// Description: LIN Description file created using Vector's DaVinci Network Designer

// Created: 16 Dec 2021 13:01:28

// Author: A048997

// Version: 0.0

// COM_MATRIX_T2_1.24.X1

LIN_description_file;
LIN_protocol_version = "2.1";
LIN_language_version = "2.1";
LIN_speed = 19.2 kbps;

Nodes {
  Master: CCM, 5 ms, 0.5 ms ;
  Slaves: HVACActuator_1, HVACActuator_2, HVACActuator_3, HVACActuator_4, HVACActuator_5 ;
}

Signals {
  HVACAct1Cmd_ConfigDir: 2, 1, CCM, HVACActuator_1 ;
  HVACAct1Cmd_ConfigEmRun: 2, 1, CCM, HVACActuator_1 ;
  HVACAct1Cmd_ConfigEmRunDir: 2, 0, CCM, HVACActuator_1 ;
  HVACAct1Cmd_ConfigMode: 2, 1, CCM, HVACActuator_1 ;
  HVACAct1Cmd_CtrlClearFlags: 4, 0, CCM, HVACActuator_1 ;
  HVACAct1Cmd_CtrlLoadData: 2, 0, CCM, HVACActuator_1 ;
  HVACAct1Cmd_CtrlStallEn: 2, 1, CCM, HVACActuator_1 ;
  HVACAct1Cmd_FPOS: 16, 65535, CCM, HVACActuator_1 ;
  HVACAct1Cmd_InitPOS: 16, 65535, CCM, HVACActuator_1 ;
  HVACAct1Cmd_NAD: 8, 255, CCM, HVACActuator_1 ;
  HVACAct1Cmd_ParamCoils: 2, 0, CCM, HVACActuator_1 ;
  HVACAct1Cmd_ParamFreq: 4, 1, CCM, HVACActuator_1 ;
  HVACAct1Cmd_ParamPosMode: 2, 2, CCM, HVACActuator_1 ;
  HVACAct2Cmd_ConfigDir: 2, 1, CCM, HVACActuator_2 ;
  HVACAct2Cmd_ConfigEmRun: 2, 1, CCM, HVACActuator_2 ;
  HVACAct2Cmd_ConfigEmRunDir: 2, 0, CCM, HVACActuator_2 ;
  HVACAct2Cmd_ConfigMode: 2, 1, CCM, HVACActuator_2 ;
  HVACAct2Cmd_CtrlClearFlags: 4, 0, CCM, HVACActuator_2 ;
  HVACAct2Cmd_CtrlLoadData: 2, 0, CCM, HVACActuator_2 ;
  HVACAct2Cmd_CtrlStallEn: 2, 1, CCM, HVACActuator_2 ;
  HVACAct2Cmd_FPOS: 16, 65535, CCM, HVACActuator_2 ;
  HVACAct2Cmd_InitPOS: 16, 65535, CCM, HVACActuator_2 ;
  HVACAct2Cmd_NAD: 8, 255, CCM, HVACActuator_2 ;
  HVACAct2Cmd_ParamCoils: 2, 0, CCM, HVACActuator_2 ;
  HVACAct2Cmd_ParamFreq: 4, 1, CCM, HVACActuator_2 ;
  HVACAct2Cmd_ParamPosMode: 2, 2, CCM, HVACActuator_2 ;
  HVACAct3Cmd_ConfigDir: 2, 1, CCM, HVACActuator_3 ;
  HVACAct3Cmd_ConfigEmRun: 2, 1, CCM, HVACActuator_3 ;
  HVACAct3Cmd_ConfigEmRunDir: 2, 0, CCM, HVACActuator_3 ;
  HVACAct3Cmd_ConfigMode: 2, 1, CCM, HVACActuator_3 ;
  HVACAct3Cmd_CtrlClearFlags: 4, 0, CCM, HVACActuator_3 ;
  HVACAct3Cmd_CtrlLoadData: 2, 0, CCM, HVACActuator_3 ;
  HVACAct3Cmd_CtrlStallEn: 2, 1, CCM, HVACActuator_3 ;
  HVACAct3Cmd_FPOS: 16, 65535, CCM, HVACActuator_3 ;
  HVACAct3Cmd_InitPOS: 16, 65535, CCM, HVACActuator_3 ;
  HVACAct3Cmd_NAD: 8, 255, CCM, HVACActuator_3 ;
  HVACAct3Cmd_ParamCoils: 2, 0, CCM, HVACActuator_3 ;
  HVACAct3Cmd_ParamFreq: 4, 1, CCM, HVACActuator_3 ;
  HVACAct3Cmd_ParamPosMode: 2, 2, CCM, HVACActuator_3 ;
  HVACAct4Cmd_ConfigDir: 2, 1, CCM, HVACActuator_4 ;
  HVACAct4Cmd_ConfigEmRun: 2, 1, CCM, HVACActuator_4 ;
  HVACAct4Cmd_ConfigEmRunDir: 2, 0, CCM, HVACActuator_4 ;
  HVACAct4Cmd_ConfigMode: 2, 1, CCM, HVACActuator_4 ;
  HVACAct4Cmd_CtrlClearFlags: 4, 0, CCM, HVACActuator_4 ;
  HVACAct4Cmd_CtrlLoadData: 2, 0, CCM, HVACActuator_4 ;
  HVACAct4Cmd_CtrlStallEn: 2, 1, CCM, HVACActuator_4 ;
  HVACAct4Cmd_FPOS: 16, 65535, CCM, HVACActuator_4 ;
  HVACAct4Cmd_InitPOS: 16, 65535, CCM, HVACActuator_4 ;
  HVACAct4Cmd_NAD: 8, 255, CCM, HVACActuator_4 ;
  HVACAct4Cmd_ParamCoils: 2, 0, CCM, HVACActuator_4 ;
  HVACAct4Cmd_ParamFreq: 4, 1, CCM, HVACActuator_4 ;
  HVACAct4Cmd_ParamPosMode: 2, 2, CCM, HVACActuator_4 ;
  HVACAct5Cmd_ConfigDir: 2, 1, CCM, HVACActuator_5 ;
  HVACAct5Cmd_ConfigEmRun: 2, 1, CCM, HVACActuator_5 ;
  HVACAct5Cmd_ConfigEmRunDir: 2, 0, CCM, HVACActuator_5 ;
  HVACAct5Cmd_ConfigMode: 2, 1, CCM, HVACActuator_5 ;
  HVACAct5Cmd_CtrlClearFlags: 4, 0, CCM, HVACActuator_5 ;
  HVACAct5Cmd_CtrlLoadData: 2, 0, CCM, HVACActuator_5 ;
  HVACAct5Cmd_CtrlStallEn: 2, 1, CCM, HVACActuator_5 ;
  HVACAct5Cmd_FPOS: 16, 65535, CCM, HVACActuator_5 ;
  HVACAct5Cmd_InitPOS: 16, 65535, CCM, HVACActuator_5 ;
  HVACAct5Cmd_NAD: 8, 255, CCM, HVACActuator_5 ;
  HVACAct5Cmd_ParamCoils: 2, 0, CCM, HVACActuator_5 ;
  HVACAct5Cmd_ParamFreq: 4, 1, CCM, HVACActuator_5 ;
  HVACAct5Cmd_ParamPosMode: 2, 2, CCM, HVACActuator_5 ;
  LIN_HVACAct1Stat_Conf2RunUpDir: 2, 3, HVACActuator_1, CCM ;
  LIN_HVACAct1Stat_Conf2SpecFnc: 2, 3, HVACActuator_1, CCM ;
  LIN_HVACAct1Stat_Conf2TorqueVar: 2, 3, HVACActuator_1, CCM ;
  LIN_HVACAct1Stat_ConfigDir: 2, 1, HVACActuator_1, CCM ;
  LIN_HVACAct1Stat_ConfigEmRun: 2, 0, HVACActuator_1, CCM ;
  LIN_HVACAct1Stat_ConfigEmRunDir: 2, 0, HVACActuator_1, CCM ;
  LIN_HVACAct1Stat_ConfigMode: 2, 1, HVACActuator_1, CCM ;
  LIN_HVACAct1Stat_CurrentPos: 16, 65535, HVACActuator_1, CCM ;
  LIN_HVACAct1Stat_ErrorElectr: 2, 0, HVACActuator_1, CCM ;
  LIN_HVACAct1Stat_ErrorSupply: 2, 0, HVACActuator_1, CCM ;
  LIN_HVACAct1Stat_ErrorTemp: 2, 0, HVACActuator_1, CCM ;
  LIN_HVACAct1Stat_NAD: 8, 255, HVACActuator_1, CCM ;
  LIN_HVACAct1Stat_ParamCoils: 2, 0, HVACActuator_1, CCM ;
  LIN_HVACAct1Stat_ParamFreq: 4, 0, HVACActuator_1, CCM ;
  LIN_HVACAct1Stat_ParamPosMode: 2, 2, HVACActuator_1, CCM ;
  LIN_HVACAct1Stat_ResponseError: 1, 0, HVACActuator_1, CCM ;
  LIN_HVACAct1Stat_StatusEmRun: 2, 0, HVACActuator_1, CCM ;
  LIN_HVACAct1Stat_StatusReset: 2, 0, HVACActuator_1, CCM ;
  LIN_HVACAct1Stat_StatusStall: 2, 0, HVACActuator_1, CCM ;
  LIN_HVACAct1Stat_StatusStallEn: 2, 0, HVACActuator_1, CCM ;
  LIN_HVACAct2Stat_Conf2RunUpDir: 2, 3, HVACActuator_2, CCM ;
  LIN_HVACAct2Stat_Conf2SpecFnc: 2, 3, HVACActuator_2, CCM ;
  LIN_HVACAct2Stat_Conf2TorqueVar: 2, 3, HVACActuator_2, CCM ;
  LIN_HVACAct2Stat_ConfigDir: 2, 1, HVACActuator_2, CCM ;
  LIN_HVACAct2Stat_ConfigEmRun: 2, 0, HVACActuator_2, CCM ;
  LIN_HVACAct2Stat_ConfigEmRunDir: 2, 0, HVACActuator_2, CCM ;
  LIN_HVACAct2Stat_ConfigMode: 2, 1, HVACActuator_2, CCM ;
  LIN_HVACAct2Stat_CurrentPos: 16, 65535, HVACActuator_2, CCM ;
  LIN_HVACAct2Stat_ErrorElectr: 2, 0, HVACActuator_2, CCM ;
  LIN_HVACAct2Stat_ErrorSupply: 2, 0, HVACActuator_2, CCM ;
  LIN_HVACAct2Stat_ErrorTemp: 2, 0, HVACActuator_2, CCM ;
  LIN_HVACAct2Stat_NAD: 8, 255, HVACActuator_2, CCM ;
  LIN_HVACAct2Stat_ParamCoils: 2, 0, HVACActuator_2, CCM ;
  LIN_HVACAct2Stat_ParamFreq: 4, 0, HVACActuator_2, CCM ;
  LIN_HVACAct2Stat_ParamPosMode: 2, 2, HVACActuator_2, CCM ;
  LIN_HVACAct2Stat_ResponseError: 1, 0, HVACActuator_2, CCM ;
  LIN_HVACAct2Stat_StatusEmRun: 2, 0, HVACActuator_2, CCM ;
  LIN_HVACAct2Stat_StatusReset: 2, 0, HVACActuator_2, CCM ;
  LIN_HVACAct2Stat_StatusStall: 2, 0, HVACActuator_2, CCM ;
  LIN_HVACAct2Stat_StatusStallEn: 2, 0, HVACActuator_2, CCM ;
  LIN_HVACAct3Stat_Conf2RunUpDir: 2, 3, HVACActuator_3, CCM ;
  LIN_HVACAct3Stat_Conf2SpecFnc: 2, 3, HVACActuator_3, CCM ;
  LIN_HVACAct3Stat_Conf2TorqueVar: 2, 3, HVACActuator_3, CCM ;
  LIN_HVACAct3Stat_ConfigDir: 2, 1, HVACActuator_3, CCM ;
  LIN_HVACAct3Stat_ConfigEmRun: 2, 0, HVACActuator_3, CCM ;
  LIN_HVACAct3Stat_ConfigEmRunDir: 2, 0, HVACActuator_3, CCM ;
  LIN_HVACAct3Stat_ConfigMode: 2, 1, HVACActuator_3, CCM ;
  LIN_HVACAct3Stat_CurrentPos: 16, 65535, HVACActuator_3, CCM ;
  LIN_HVACAct3Stat_ErrorElectr: 2, 0, HVACActuator_3, CCM ;
  LIN_HVACAct3Stat_ErrorSupply: 2, 0, HVACActuator_3, CCM ;
  LIN_HVACAct3Stat_ErrorTemp: 2, 0, HVACActuator_3, CCM ;
  LIN_HVACAct3Stat_NAD: 8, 255, HVACActuator_3, CCM ;
  LIN_HVACAct3Stat_ParamCoils: 2, 0, HVACActuator_3, CCM ;
  LIN_HVACAct3Stat_ParamFreq: 4, 0, HVACActuator_3, CCM ;
  LIN_HVACAct3Stat_ParamPosMode: 2, 2, HVACActuator_3, CCM ;
  LIN_HVACAct3Stat_ResponseError: 1, 0, HVACActuator_3, CCM ;
  LIN_HVACAct3Stat_StatusEmRun: 2, 0, HVACActuator_3, CCM ;
  LIN_HVACAct3Stat_StatusReset: 2, 0, HVACActuator_3, CCM ;
  LIN_HVACAct3Stat_StatusStall: 2, 0, HVACActuator_3, CCM ;
  LIN_HVACAct3Stat_StatusStallEn: 2, 0, HVACActuator_3, CCM ;
  LIN_HVACAct4Stat_Conf2RunUpDir: 2, 3, HVACActuator_4, CCM ;
  LIN_HVACAct4Stat_Conf2SpecFnc: 2, 3, HVACActuator_4, CCM ;
  LIN_HVACAct4Stat_Conf2TorqueVar: 2, 3, HVACActuator_4, CCM ;
  LIN_HVACAct4Stat_ConfigDir: 2, 1, HVACActuator_4, CCM ;
  LIN_HVACAct4Stat_ConfigEmRun: 2, 0, HVACActuator_4, CCM ;
  LIN_HVACAct4Stat_ConfigEmRunDir: 2, 0, HVACActuator_4, CCM ;
  LIN_HVACAct4Stat_ConfigMode: 2, 1, HVACActuator_4, CCM ;
  LIN_HVACAct4Stat_CurrentPos: 16, 65535, HVACActuator_4, CCM ;
  LIN_HVACAct4Stat_ErrorElectr: 2, 0, HVACActuator_4, CCM ;
  LIN_HVACAct4Stat_ErrorSupply: 2, 0, HVACActuator_4, CCM ;
  LIN_HVACAct4Stat_ErrorTemp: 2, 0, HVACActuator_4, CCM ;
  LIN_HVACAct4Stat_NAD: 8, 255, HVACActuator_4, CCM ;
  LIN_HVACAct4Stat_ParamCoils: 2, 0, HVACActuator_4, CCM ;
  LIN_HVACAct4Stat_ParamFreq: 4, 0, HVACActuator_4, CCM ;
  LIN_HVACAct4Stat_ParamPosMode: 2, 2, HVACActuator_4, CCM ;
  LIN_HVACAct4Stat_ResponseError: 1, 0, HVACActuator_4, CCM ;
  LIN_HVACAct4Stat_StatusEmRun: 2, 0, HVACActuator_4, CCM ;
  LIN_HVACAct4Stat_StatusReset: 2, 0, HVACActuator_4, CCM ;
  LIN_HVACAct4Stat_StatusStall: 2, 0, HVACActuator_4, CCM ;
  LIN_HVACAct4Stat_StatusStallEn: 2, 0, HVACActuator_4, CCM ;
  LIN_HVACAct5Stat_Conf2RunUpDir: 2, 3, HVACActuator_5, CCM ;
  LIN_HVACAct5Stat_Conf2SpecFnc: 2, 3, HVACActuator_5, CCM ;
  LIN_HVACAct5Stat_Conf2TorqueVar: 2, 3, HVACActuator_5, CCM ;
  LIN_HVACAct5Stat_ConfigDir: 2, 1, HVACActuator_5, CCM ;
  LIN_HVACAct5Stat_ConfigEmRun: 2, 0, HVACActuator_5, CCM ;
  LIN_HVACAct5Stat_ConfigEmRunDir: 2, 0, HVACActuator_5, CCM ;
  LIN_HVACAct5Stat_ConfigMode: 2, 1, HVACActuator_5, CCM ;
  LIN_HVACAct5Stat_CurrentPos: 16, 65535, HVACActuator_5, CCM ;
  LIN_HVACAct5Stat_ErrorElectr: 2, 0, HVACActuator_5, CCM ;
  LIN_HVACAct5Stat_ErrorSupply: 2, 0, HVACActuator_5, CCM ;
  LIN_HVACAct5Stat_ErrorTemp: 2, 0, HVACActuator_5, CCM ;
  LIN_HVACAct5Stat_NAD: 8, 255, HVACActuator_5, CCM ;
  LIN_HVACAct5Stat_ParamCoils: 2, 0, HVACActuator_5, CCM ;
  LIN_HVACAct5Stat_ParamFreq: 4, 0, HVACActuator_5, CCM ;
  LIN_HVACAct5Stat_ParamPosMode: 2, 2, HVACActuator_5, CCM ;
  LIN_HVACAct5Stat_ResponseError: 1, 0, HVACActuator_5, CCM ;
  LIN_HVACAct5Stat_StatusEmRun: 2, 0, HVACActuator_5, CCM ;
  LIN_HVACAct5Stat_StatusReset: 2, 0, HVACActuator_5, CCM ;
  LIN_HVACAct5Stat_StatusStall: 2, 0, HVACActuator_5, CCM ;
  LIN_HVACAct5Stat_StatusStallEn: 2, 0, HVACActuator_5, CCM ;
}

Frames {
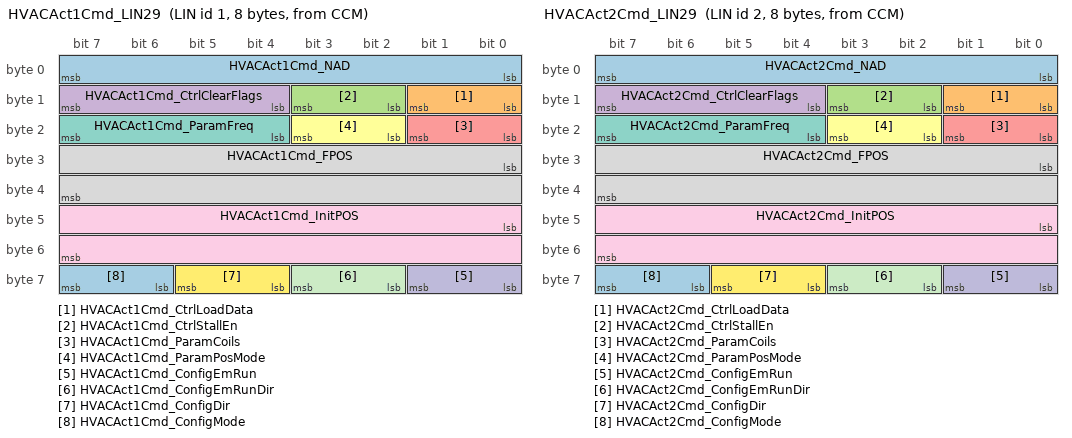
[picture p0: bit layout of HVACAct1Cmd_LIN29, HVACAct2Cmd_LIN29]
  HVACAct1Cmd_LIN29: 1, CCM, 8 {
    HVACAct1Cmd_NAD, 0 ;
    HVACAct1Cmd_CtrlLoadData, 8 ;
    HVACAct1Cmd_CtrlStallEn, 10 ;
    HVACAct1Cmd_CtrlClearFlags, 12 ;
    HVACAct1Cmd_ParamCoils, 16 ;
    HVACAct1Cmd_ParamPosMode, 18 ;
    HVACAct1Cmd_ParamFreq, 20 ;
    HVACAct1Cmd_FPOS, 24 ;
    HVACAct1Cmd_InitPOS, 40 ;
    HVACAct1Cmd_ConfigEmRun, 56 ;
    HVACAct1Cmd_ConfigEmRunDir, 58 ;
    HVACAct1Cmd_ConfigDir, 60 ;
    HVACAct1Cmd_ConfigMode, 62 ;
  }
  HVACAct1Sta_LIN29: 33, HVACActuator_1, 8 {
    LIN_HVACAct1Stat_ResponseError, 0 ;
    LIN_HVACAct1Stat_ErrorTemp, 2 ;
    LIN_HVACAct1Stat_ErrorElectr, 4 ;
    LIN_HVACAct1Stat_ErrorSupply, 6 ;
    LIN_HVACAct1Stat_StatusEmRun, 8 ;
    LIN_HVACAct1Stat_StatusStallEn, 10 ;
    LIN_HVACAct1Stat_StatusStall, 12 ;
    LIN_HVACAct1Stat_StatusReset, 14 ;
    LIN_HVACAct1Stat_ParamCoils, 16 ;
    LIN_HVACAct1Stat_ParamPosMode, 18 ;
    LIN_HVACAct1Stat_ParamFreq, 20 ;
    LIN_HVACAct1Stat_CurrentPos, 24 ;
    LIN_HVACAct1Stat_Conf2RunUpDir, 40 ;
    LIN_HVACAct1Stat_Conf2TorqueVar, 42 ;
    LIN_HVACAct1Stat_Conf2SpecFnc, 44 ;
    LIN_HVACAct1Stat_NAD, 48 ;
    LIN_HVACAct1Stat_ConfigEmRun, 56 ;
    LIN_HVACAct1Stat_ConfigEmRunDir, 58 ;
    LIN_HVACAct1Stat_ConfigDir, 60 ;
    LIN_HVACAct1Stat_ConfigMode, 62 ;
  }
  HVACAct2Cmd_LIN29: 2, CCM, 8 {
    HVACAct2Cmd_NAD, 0 ;
    HVACAct2Cmd_CtrlLoadData, 8 ;
    HVACAct2Cmd_CtrlStallEn, 10 ;
    HVACAct2Cmd_CtrlClearFlags, 12 ;
    HVACAct2Cmd_ParamCoils, 16 ;
    HVACAct2Cmd_ParamPosMode, 18 ;
    HVACAct2Cmd_ParamFreq, 20 ;
    HVACAct2Cmd_FPOS, 24 ;
    HVACAct2Cmd_InitPOS, 40 ;
    HVACAct2Cmd_ConfigEmRun, 56 ;
    HVACAct2Cmd_ConfigEmRunDir, 58 ;
    HVACAct2Cmd_ConfigDir, 60 ;
    HVACAct2Cmd_ConfigMode, 62 ;
  }
  HVACAct2Sta_LIN29: 34, HVACActuator_2, 8 {
    LIN_HVACAct2Stat_ResponseError, 0 ;
    LIN_HVACAct2Stat_ErrorTemp, 2 ;
    LIN_HVACAct2Stat_ErrorElectr, 4 ;
    LIN_HVACAct2Stat_ErrorSupply, 6 ;
    LIN_HVACAct2Stat_StatusEmRun, 8 ;
    LIN_HVACAct2Stat_StatusStallEn, 10 ;
    LIN_HVACAct2Stat_StatusStall, 12 ;
    LIN_HVACAct2Stat_StatusReset, 14 ;
    LIN_HVACAct2Stat_ParamCoils, 16 ;
    LIN_HVACAct2Stat_ParamPosMode, 18 ;
    LIN_HVACAct2Stat_ParamFreq, 20 ;
    LIN_HVACAct2Stat_CurrentPos, 24 ;
    LIN_HVACAct2Stat_Conf2RunUpDir, 40 ;
    LIN_HVACAct2Stat_Conf2TorqueVar, 42 ;
    LIN_HVACAct2Stat_Conf2SpecFnc, 44 ;
    LIN_HVACAct2Stat_NAD, 48 ;
    LIN_HVACAct2Stat_ConfigEmRun, 56 ;
    LIN_HVACAct2Stat_ConfigEmRunDir, 58 ;
    LIN_HVACAct2Stat_ConfigDir, 60 ;
    LIN_HVACAct2Stat_ConfigMode, 62 ;
  }
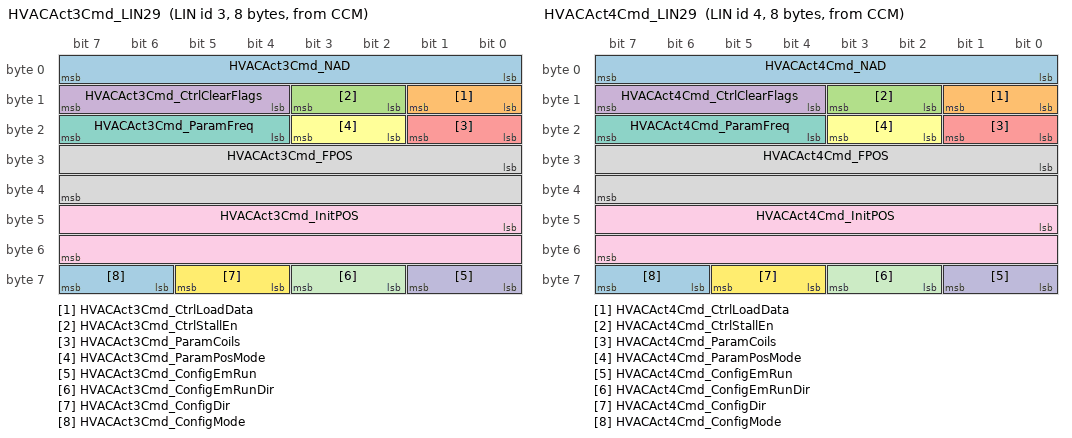
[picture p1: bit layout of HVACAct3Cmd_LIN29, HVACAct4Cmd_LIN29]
  HVACAct3Cmd_LIN29: 3, CCM, 8 {
    HVACAct3Cmd_NAD, 0 ;
    HVACAct3Cmd_CtrlLoadData, 8 ;
    HVACAct3Cmd_CtrlStallEn, 10 ;
    HVACAct3Cmd_CtrlClearFlags, 12 ;
    HVACAct3Cmd_ParamCoils, 16 ;
    HVACAct3Cmd_ParamPosMode, 18 ;
    HVACAct3Cmd_ParamFreq, 20 ;
    HVACAct3Cmd_FPOS, 24 ;
    HVACAct3Cmd_InitPOS, 40 ;
    HVACAct3Cmd_ConfigEmRun, 56 ;
    HVACAct3Cmd_ConfigEmRunDir, 58 ;
    HVACAct3Cmd_ConfigDir, 60 ;
    HVACAct3Cmd_ConfigMode, 62 ;
  }
  HVACAct3Sta_LIN29: 35, HVACActuator_3, 8 {
    LIN_HVACAct3Stat_ResponseError, 0 ;
    LIN_HVACAct3Stat_ErrorTemp, 2 ;
    LIN_HVACAct3Stat_ErrorElectr, 4 ;
    LIN_HVACAct3Stat_ErrorSupply, 6 ;
    LIN_HVACAct3Stat_StatusEmRun, 8 ;
    LIN_HVACAct3Stat_StatusStallEn, 10 ;
    LIN_HVACAct3Stat_StatusStall, 12 ;
    LIN_HVACAct3Stat_StatusReset, 14 ;
    LIN_HVACAct3Stat_ParamCoils, 16 ;
    LIN_HVACAct3Stat_ParamPosMode, 18 ;
    LIN_HVACAct3Stat_ParamFreq, 20 ;
    LIN_HVACAct3Stat_CurrentPos, 24 ;
    LIN_HVACAct3Stat_Conf2RunUpDir, 40 ;
    LIN_HVACAct3Stat_Conf2TorqueVar, 42 ;
    LIN_HVACAct3Stat_Conf2SpecFnc, 44 ;
    LIN_HVACAct3Stat_NAD, 48 ;
    LIN_HVACAct3Stat_ConfigEmRun, 56 ;
    LIN_HVACAct3Stat_ConfigEmRunDir, 58 ;
    LIN_HVACAct3Stat_ConfigDir, 60 ;
    LIN_HVACAct3Stat_ConfigMode, 62 ;
  }
  HVACAct4Cmd_LIN29: 4, CCM, 8 {
    HVACAct4Cmd_NAD, 0 ;
    HVACAct4Cmd_CtrlLoadData, 8 ;
    HVACAct4Cmd_CtrlStallEn, 10 ;
    HVACAct4Cmd_CtrlClearFlags, 12 ;
    HVACAct4Cmd_ParamCoils, 16 ;
    HVACAct4Cmd_ParamPosMode, 18 ;
    HVACAct4Cmd_ParamFreq, 20 ;
    HVACAct4Cmd_FPOS, 24 ;
    HVACAct4Cmd_InitPOS, 40 ;
    HVACAct4Cmd_ConfigEmRun, 56 ;
    HVACAct4Cmd_ConfigEmRunDir, 58 ;
    HVACAct4Cmd_ConfigDir, 60 ;
    HVACAct4Cmd_ConfigMode, 62 ;
  }
  HVACAct4Sta_LIN29: 36, HVACActuator_4, 8 {
    LIN_HVACAct4Stat_ResponseError, 0 ;
    LIN_HVACAct4Stat_ErrorTemp, 2 ;
    LIN_HVACAct4Stat_ErrorElectr, 4 ;
    LIN_HVACAct4Stat_ErrorSupply, 6 ;
    LIN_HVACAct4Stat_StatusEmRun, 8 ;
    LIN_HVACAct4Stat_StatusStallEn, 10 ;
    LIN_HVACAct4Stat_StatusStall, 12 ;
    LIN_HVACAct4Stat_StatusReset, 14 ;
    LIN_HVACAct4Stat_ParamCoils, 16 ;
    LIN_HVACAct4Stat_ParamPosMode, 18 ;
    LIN_HVACAct4Stat_ParamFreq, 20 ;
    LIN_HVACAct4Stat_CurrentPos, 24 ;
    LIN_HVACAct4Stat_Conf2RunUpDir, 40 ;
    LIN_HVACAct4Stat_Conf2TorqueVar, 42 ;
    LIN_HVACAct4Stat_Conf2SpecFnc, 44 ;
    LIN_HVACAct4Stat_NAD, 48 ;
    LIN_HVACAct4Stat_ConfigEmRun, 56 ;
    LIN_HVACAct4Stat_ConfigEmRunDir, 58 ;
    LIN_HVACAct4Stat_ConfigDir, 60 ;
    LIN_HVACAct4Stat_ConfigMode, 62 ;
  }
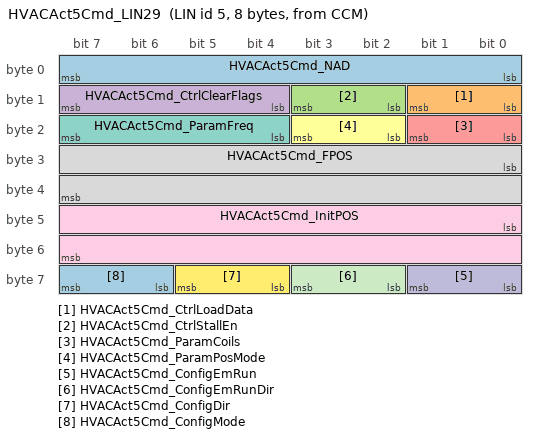
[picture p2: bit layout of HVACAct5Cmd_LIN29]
  HVACAct5Cmd_LIN29: 5, CCM, 8 {
    HVACAct5Cmd_NAD, 0 ;
    HVACAct5Cmd_CtrlLoadData, 8 ;
    HVACAct5Cmd_CtrlStallEn, 10 ;
    HVACAct5Cmd_CtrlClearFlags, 12 ;
    HVACAct5Cmd_ParamCoils, 16 ;
    HVACAct5Cmd_ParamPosMode, 18 ;
    HVACAct5Cmd_ParamFreq, 20 ;
    HVACAct5Cmd_FPOS, 24 ;
    HVACAct5Cmd_InitPOS, 40 ;
    HVACAct5Cmd_ConfigEmRun, 56 ;
    HVACAct5Cmd_ConfigEmRunDir, 58 ;
    HVACAct5Cmd_ConfigDir, 60 ;
    HVACAct5Cmd_ConfigMode, 62 ;
  }
  HVACAct5Sta_LIN29: 37, HVACActuator_5, 8 {
    LIN_HVACAct5Stat_ResponseError, 0 ;
    LIN_HVACAct5Stat_ErrorTemp, 2 ;
    LIN_HVACAct5Stat_ErrorElectr, 4 ;
    LIN_HVACAct5Stat_ErrorSupply, 6 ;
    LIN_HVACAct5Stat_StatusEmRun, 8 ;
    LIN_HVACAct5Stat_StatusStallEn, 10 ;
    LIN_HVACAct5Stat_StatusStall, 12 ;
    LIN_HVACAct5Stat_StatusReset, 14 ;
    LIN_HVACAct5Stat_ParamCoils, 16 ;
    LIN_HVACAct5Stat_ParamPosMode, 18 ;
    LIN_HVACAct5Stat_ParamFreq, 20 ;
    LIN_HVACAct5Stat_CurrentPos, 24 ;
    LIN_HVACAct5Stat_Conf2RunUpDir, 40 ;
    LIN_HVACAct5Stat_Conf2TorqueVar, 42 ;
    LIN_HVACAct5Stat_Conf2SpecFnc, 44 ;
    LIN_HVACAct5Stat_NAD, 48 ;
    LIN_HVACAct5Stat_ConfigEmRun, 56 ;
    LIN_HVACAct5Stat_ConfigEmRunDir, 58 ;
    LIN_HVACAct5Stat_ConfigDir, 60 ;
    LIN_HVACAct5Stat_ConfigMode, 62 ;
  }
}

Node_attributes {
  HVACActuator_1{
    LIN_protocol = "2.1" ;
    configured_NAD = 0x21 ;
    initial_NAD = 0x21 ;
    product_id = 0x76, 0x2, 85 ;
    response_error = LIN_HVACAct1Stat_ResponseError ;
    N_As_timeout = 1000 ms ;
    N_Cr_timeout = 1000 ms ;
    configurable_frames {
      HVACAct1Sta_LIN29 ;
      HVACAct1Cmd_LIN29 ;
    }
  }
  HVACActuator_2{
    LIN_protocol = "2.1" ;
    configured_NAD = 0x22 ;
    initial_NAD = 0x22 ;
    product_id = 0x76, 0x2, 85 ;
    response_error = LIN_HVACAct2Stat_ResponseError ;
    N_As_timeout = 1000 ms ;
    N_Cr_timeout = 1000 ms ;
    configurable_frames {
      HVACAct2Sta_LIN29 ;
      HVACAct2Cmd_LIN29 ;
    }
  }
  HVACActuator_3{
    LIN_protocol = "2.1" ;
    configured_NAD = 0x23 ;
    initial_NAD = 0x23 ;
    product_id = 0x76, 0x2, 85 ;
    response_error = LIN_HVACAct3Stat_ResponseError ;
    N_As_timeout = 1000 ms ;
    N_Cr_timeout = 1000 ms ;
    configurable_frames {
      HVACAct3Sta_LIN29 ;
      HVACAct3Cmd_LIN29 ;
    }
  }
  HVACActuator_4{
    LIN_protocol = "2.1" ;
    configured_NAD = 0x24 ;
    initial_NAD = 0x24 ;
    product_id = 0x76, 0x2, 85 ;
    response_error = LIN_HVACAct4Stat_ResponseError ;
    N_As_timeout = 1000 ms ;
    N_Cr_timeout = 1000 ms ;
    configurable_frames {
      HVACAct4Sta_LIN29 ;
      HVACAct4Cmd_LIN29 ;
    }
  }
  HVACActuator_5{
    LIN_protocol = "2.1" ;
    configured_NAD = 0x25 ;
    initial_NAD = 0x25 ;
    product_id = 0x76, 0x2, 85 ;
    response_error = LIN_HVACAct5Stat_ResponseError ;
    N_As_timeout = 1000 ms ;
    N_Cr_timeout = 1000 ms ;
    configurable_frames {
      HVACAct5Sta_LIN29 ;
      HVACAct5Cmd_LIN29 ;
    }
  }
}

Schedule_tables {
 Table0 {
    HVACAct1Cmd_LIN29 delay 20 ms ;
    HVACAct1Sta_LIN29 delay 20 ms ;
    HVACAct2Cmd_LIN29 delay 20 ms ;
    HVACAct2Sta_LIN29 delay 20 ms ;
    HVACAct3Cmd_LIN29 delay 20 ms ;
    HVACAct3Sta_LIN29 delay 20 ms ;
    HVACAct4Cmd_LIN29 delay 20 ms ;
    HVACAct4Sta_LIN29 delay 20 ms ;
    HVACAct5Cmd_LIN29 delay 20 ms ;
    HVACAct5Sta_LIN29 delay 20 ms ;
  }
 MasterReq_Table {
    MasterReq delay 20 ms ;
  }
 SlaveResp_Table {
    SlaveResp delay 20 ms ;
  }
}

Signal_encoding_types {
  HVACAct1Cmd_ConfigDir {
    logical_value, 0, "HVACActConfigDir_MovermentsInCW" ;
    logical_value, 1, "HVACActConfigDir_MovementsInCCW" ;
    logical_value, 2, "HVACActConfigDir_NA1" ;
    logical_value, 3, "HVACActConfigDir_NA2" ;
  }
  HVACAct1Cmd_ConfigEmRun {
    logical_value, 0, "HVACActConfigEmRunCmd_EmergencyRunDisabled" ;
    logical_value, 1, "HVACActConfigEmRunCmd_EmergencyRunEnabled" ;
    logical_value, 2, "HVACActConfigEmRunCmd_NA1" ;
    logical_value, 3, "HVACActConfigEmRunCmd_NA2" ;
  }
  HVACAct1Cmd_ConfigEmRunDir {
    logical_value, 0, "HVACActConfigEmRunDir_EmergencyRunLowEndStop" ;
    logical_value, 1, "HVACActConfigEmRunDir_EmergencyRunHighEndStop" ;
    logical_value, 2, "HVACActConfigEmRunDir_NA1" ;
    logical_value, 3, "HVACActConfigEmRunDir_NA2" ;
  }
  HVACAct1Cmd_ConfigMode {
    logical_value, 0, "HVACActConfigMode_NormalMode" ;
    logical_value, 1, "HVACActConfigMode_StopMode" ;
    logical_value, 2, "HVACActConfigMode_NA1" ;
    logical_value, 3, "HVACActConfigMode_NA2" ;
  }
  HVACAct1Cmd_CtrlClearFlags {
    physical_value, 0, 15, 1, 0, "NotApplicable" ;
  }
  HVACAct1Cmd_CtrlLoadData {
    logical_value, 0, "HVACActCtrlLoadData_DoNotSaveInNVRAM" ;
    logical_value, 1, "HVACActCtrlLoadData_SaveDataInNVRAM" ;
    logical_value, 2, "HVACActCtrlLoadData_Reserved" ;
    logical_value, 3, "HVACActCtrlLoadData_Invalid" ;
  }
  HVACAct1Cmd_CtrlStallEn {
    logical_value, 0, "HVACActCtrlStallEn_Off" ;
    logical_value, 1, "HVACActCtrlStallEn_On" ;
    logical_value, 2, "HVACActCtrlStallEn_NA1" ;
    logical_value, 3, "HVACActCtrlStallEn_NA2" ;
  }
  HVACAct1Cmd_ParamCoils {
    logical_value, 0, "HVACActParamCoils_CoilsNotEnergizedWhenActStopped" ;
    logical_value, 1, "HVACActParamCoils_CoilsNEnergizedWhenActStopped" ;
    logical_value, 2, "HVACActParamCoils_Reserved" ;
    logical_value, 3, "HVACActParamCoils_Invalid" ;
  }
  HVACAct1Cmd_ParamFreq {
    logical_value, 0, "HVACActParamFreq_Stopped" ;
    logical_value, 1, "HVACActParamFreq_240_320sps" ;
    logical_value, 2, "HVACActParamFreq_320sps" ;
    logical_value, 3, "HVACActParamFreq_430sps" ;
    logical_value, 4, "HVACActParamFreq_540sps1" ;
    logical_value, 5, "HVACActParamFreq_540sps2" ;
    logical_value, 6, "HVACActParamFreq_Reserved1" ;
    logical_value, 7, "HVACActParamFreq_Reserved2" ;
    logical_value, 8, "HVACActParamFreq_Reserved3" ;
    logical_value, 9, "HVACActParamFreq_Reserved4" ;
    logical_value, 10, "HVACActParamFreq_Reserved5" ;
    logical_value, 11, "HVACActParamFreq_Reserved6" ;
    logical_value, 12, "HVACActParamFreq_Reserved7" ;
    logical_value, 13, "HVACActParamFreq_Reserved8" ;
    logical_value, 14, "HVACActParamFreq_Reserved9" ;
    logical_value, 15, "HVACActParamFreq_Invalid" ;
  }
  HVACAct1Cmd_ParamPosMode {
    logical_value, 0, "HVACActParamPosMode_SelectionOfFPOS" ;
    logical_value, 1, "HVACActParamPosMode_SelectionOfInitPOS" ;
    logical_value, 2, "HVACActParamPosMode_NoSelectedPosition" ;
    logical_value, 3, "HVACActParamPosMode_Invalid" ;
  }
  HVACAct2Cmd_ConfigDir {
    logical_value, 0, "HVACActConfigDir_MovermentsInCW" ;
    logical_value, 1, "HVACActConfigDir_MovementsInCCW" ;
    logical_value, 2, "HVACActConfigDir_NA1" ;
    logical_value, 3, "HVACActConfigDir_NA2" ;
  }
  HVACAct2Cmd_ConfigEmRun {
    logical_value, 0, "HVACActConfigEmRunCmd_EmergencyRunDisabled" ;
    logical_value, 1, "HVACActConfigEmRunCmd_EmergencyRunEnabled" ;
    logical_value, 2, "HVACActConfigEmRunCmd_NA1" ;
    logical_value, 3, "HVACActConfigEmRunCmd_NA2" ;
  }
  HVACAct2Cmd_ConfigEmRunDir {
    logical_value, 0, "HVACActConfigEmRunDir_EmergencyRunLowEndStop" ;
    logical_value, 1, "HVACActConfigEmRunDir_EmergencyRunHighEndStop" ;
    logical_value, 2, "HVACActConfigEmRunDir_NA1" ;
    logical_value, 3, "HVACActConfigEmRunDir_NA2" ;
  }
  HVACAct2Cmd_ConfigMode {
    logical_value, 0, "HVACActConfigMode_NormalMode" ;
    logical_value, 1, "HVACActConfigMode_StopMode" ;
    logical_value, 2, "HVACActConfigMode_NA1" ;
    logical_value, 3, "HVACActConfigMode_NA2" ;
  }
  HVACAct2Cmd_CtrlClearFlags {
    physical_value, 0, 15, 1, 0, "NotApplicable" ;
  }
  HVACAct2Cmd_CtrlLoadData {
    logical_value, 0, "HVACActCtrlLoadData_DoNotSaveInNVRAM" ;
    logical_value, 1, "HVACActCtrlLoadData_SaveDataInNVRAM" ;
    logical_value, 2, "HVACActCtrlLoadData_Reserved" ;
    logical_value, 3, "HVACActCtrlLoadData_Invalid" ;
  }
  HVACAct2Cmd_CtrlStallEn {
    logical_value, 0, "HVACActCtrlStallEn_Off" ;
    logical_value, 1, "HVACActCtrlStallEn_On" ;
    logical_value, 2, "HVACActCtrlStallEn_NA1" ;
    logical_value, 3, "HVACActCtrlStallEn_NA2" ;
  }
  HVACAct2Cmd_ParamCoils {
    logical_value, 0, "HVACActParamCoils_CoilsNotEnergizedWhenActStopped" ;
    logical_value, 1, "HVACActParamCoils_CoilsNEnergizedWhenActStopped" ;
    logical_value, 2, "HVACActParamCoils_Reserved" ;
    logical_value, 3, "HVACActParamCoils_Invalid" ;
  }
  HVACAct2Cmd_ParamFreq {
    logical_value, 0, "HVACActParamFreq_Stopped" ;
    logical_value, 1, "HVACActParamFreq_240_320sps" ;
    logical_value, 2, "HVACActParamFreq_320sps" ;
    logical_value, 3, "HVACActParamFreq_430sps" ;
    logical_value, 4, "HVACActParamFreq_540sps1" ;
    logical_value, 5, "HVACActParamFreq_540sps2" ;
    logical_value, 6, "HVACActParamFreq_Reserved1" ;
    logical_value, 7, "HVACActParamFreq_Reserved2" ;
    logical_value, 8, "HVACActParamFreq_Reserved3" ;
    logical_value, 9, "HVACActParamFreq_Reserved4" ;
    logical_value, 10, "HVACActParamFreq_Reserved5" ;
    logical_value, 11, "HVACActParamFreq_Reserved6" ;
    logical_value, 12, "HVACActParamFreq_Reserved7" ;
    logical_value, 13, "HVACActParamFreq_Reserved8" ;
    logical_value, 14, "HVACActParamFreq_Reserved9" ;
    logical_value, 15, "HVACActParamFreq_Invalid" ;
  }
  HVACAct2Cmd_ParamPosMode {
    logical_value, 0, "HVACActParamPosMode_SelectionOfFPOS" ;
    logical_value, 1, "HVACActParamPosMode_SelectionOfInitPOS" ;
    logical_value, 2, "HVACActParamPosMode_NoSelectedPosition" ;
    logical_value, 3, "HVACActParamPosMode_Invalid" ;
  }
  HVACAct3Cmd_ConfigDir {
    logical_value, 0, "HVACActConfigDir_MovermentsInCW" ;
    logical_value, 1, "HVACActConfigDir_MovementsInCCW" ;
    logical_value, 2, "HVACActConfigDir_NA1" ;
    logical_value, 3, "HVACActConfigDir_NA2" ;
  }
  HVACAct3Cmd_ConfigEmRun {
    logical_value, 0, "HVACActConfigEmRunCmd_EmergencyRunDisabled" ;
    logical_value, 1, "HVACActConfigEmRunCmd_EmergencyRunEnabled" ;
    logical_value, 2, "HVACActConfigEmRunCmd_NA1" ;
    logical_value, 3, "HVACActConfigEmRunCmd_NA2" ;
  }
  HVACAct3Cmd_ConfigEmRunDir {
    logical_value, 0, "HVACActConfigEmRunDir_EmergencyRunLowEndStop" ;
    logical_value, 1, "HVACActConfigEmRunDir_EmergencyRunHighEndStop" ;
    logical_value, 2, "HVACActConfigEmRunDir_NA1" ;
    logical_value, 3, "HVACActConfigEmRunDir_NA2" ;
  }
  HVACAct3Cmd_ConfigMode {
    logical_value, 0, "HVACActConfigMode_NormalMode" ;
    logical_value, 1, "HVACActConfigMode_StopMode" ;
    logical_value, 2, "HVACActConfigMode_NA1" ;
    logical_value, 3, "HVACActConfigMode_NA2" ;
  }
  HVACAct3Cmd_CtrlClearFlags {
    physical_value, 0, 15, 1, 0, "NotApplicable" ;
  }
  HVACAct3Cmd_CtrlLoadData {
    logical_value, 0, "HVACActCtrlLoadData_DoNotSaveInNVRAM" ;
    logical_value, 1, "HVACActCtrlLoadData_SaveDataInNVRAM" ;
    logical_value, 2, "HVACActCtrlLoadData_Reserved" ;
    logical_value, 3, "HVACActCtrlLoadData_Invalid" ;
  }
  HVACAct3Cmd_CtrlStallEn {
    logical_value, 0, "HVACActCtrlStallEn_Off" ;
    logical_value, 1, "HVACActCtrlStallEn_On" ;
    logical_value, 2, "HVACActCtrlStallEn_NA1" ;
    logical_value, 3, "HVACActCtrlStallEn_NA2" ;
  }
  HVACAct3Cmd_ParamCoils {
    logical_value, 0, "HVACActParamCoils_CoilsNotEnergizedWhenActStopped" ;
    logical_value, 1, "HVACActParamCoils_CoilsNEnergizedWhenActStopped" ;
    logical_value, 2, "HVACActParamCoils_Reserved" ;
    logical_value, 3, "HVACActParamCoils_Invalid" ;
  }
  HVACAct3Cmd_ParamFreq {
    logical_value, 0, "HVACActParamFreq_Stopped" ;
    logical_value, 1, "HVACActParamFreq_240_320sps" ;
    logical_value, 2, "HVACActParamFreq_320sps" ;
    logical_value, 3, "HVACActParamFreq_430sps" ;
    logical_value, 4, "HVACActParamFreq_540sps1" ;
    logical_value, 5, "HVACActParamFreq_540sps2" ;
    logical_value, 6, "HVACActParamFreq_Reserved1" ;
    logical_value, 7, "HVACActParamFreq_Reserved2" ;
    logical_value, 8, "HVACActParamFreq_Reserved3" ;
    logical_value, 9, "HVACActParamFreq_Reserved4" ;
    logical_value, 10, "HVACActParamFreq_Reserved5" ;
    logical_value, 11, "HVACActParamFreq_Reserved6" ;
    logical_value, 12, "HVACActParamFreq_Reserved7" ;
    logical_value, 13, "HVACActParamFreq_Reserved8" ;
    logical_value, 14, "HVACActParamFreq_Reserved9" ;
    logical_value, 15, "HVACActParamFreq_Invalid" ;
  }
  HVACAct3Cmd_ParamPosMode {
    logical_value, 0, "HVACActParamPosMode_SelectionOfFPOS" ;
    logical_value, 1, "HVACActParamPosMode_SelectionOfInitPOS" ;
    logical_value, 2, "HVACActParamPosMode_NoSelectedPosition" ;
    logical_value, 3, "HVACActParamPosMode_Invalid" ;
  }
  HVACAct4Cmd_ConfigDir {
    logical_value, 0, "HVACActConfigDir_MovermentsInCW" ;
    logical_value, 1, "HVACActConfigDir_MovementsInCCW" ;
    logical_value, 2, "HVACActConfigDir_NA1" ;
    logical_value, 3, "HVACActConfigDir_NA2" ;
  }
  HVACAct4Cmd_ConfigEmRun {
    logical_value, 0, "HVACActConfigEmRunCmd_EmergencyRunDisabled" ;
    logical_value, 1, "HVACActConfigEmRunCmd_EmergencyRunEnabled" ;
    logical_value, 2, "HVACActConfigEmRunCmd_NA1" ;
    logical_value, 3, "HVACActConfigEmRunCmd_NA2" ;
  }
  HVACAct4Cmd_ConfigEmRunDir {
    logical_value, 0, "HVACActConfigEmRunDir_EmergencyRunLowEndStop" ;
    logical_value, 1, "HVACActConfigEmRunDir_EmergencyRunHighEndStop" ;
    logical_value, 2, "HVACActConfigEmRunDir_NA1" ;
    logical_value, 3, "HVACActConfigEmRunDir_NA2" ;
  }
  HVACAct4Cmd_ConfigMode {
    logical_value, 0, "HVACActConfigMode_NormalMode" ;
    logical_value, 1, "HVACActConfigMode_StopMode" ;
    logical_value, 2, "HVACActConfigMode_NA1" ;
    logical_value, 3, "HVACActConfigMode_NA2" ;
  }
  HVACAct4Cmd_CtrlClearFlags {
    physical_value, 0, 15, 1, 0, "NotApplicable" ;
  }
  HVACAct4Cmd_CtrlLoadData {
    logical_value, 0, "HVACActCtrlLoadData_DoNotSaveInNVRAM" ;
    logical_value, 1, "HVACActCtrlLoadData_SaveDataInNVRAM" ;
    logical_value, 2, "HVACActCtrlLoadData_Reserved" ;
    logical_value, 3, "HVACActCtrlLoadData_Invalid" ;
  }
  HVACAct4Cmd_CtrlStallEn {
    logical_value, 0, "HVACActCtrlStallEn_Off" ;
    logical_value, 1, "HVACActCtrlStallEn_On" ;
    logical_value, 2, "HVACActCtrlStallEn_NA1" ;
    logical_value, 3, "HVACActCtrlStallEn_NA2" ;
  }
  HVACAct4Cmd_ParamCoils {
    logical_value, 0, "HVACActParamCoils_CoilsNotEnergizedWhenActStopped" ;
    logical_value, 1, "HVACActParamCoils_CoilsNEnergizedWhenActStopped" ;
    logical_value, 2, "HVACActParamCoils_Reserved" ;
    logical_value, 3, "HVACActParamCoils_Invalid" ;
  }
  HVACAct4Cmd_ParamFreq {
    logical_value, 0, "HVACActParamFreq_Stopped" ;
    logical_value, 1, "HVACActParamFreq_240_320sps" ;
    logical_value, 2, "HVACActParamFreq_320sps" ;
    logical_value, 3, "HVACActParamFreq_430sps" ;
    logical_value, 4, "HVACActParamFreq_540sps1" ;
    logical_value, 5, "HVACActParamFreq_540sps2" ;
    logical_value, 6, "HVACActParamFreq_Reserved1" ;
    logical_value, 7, "HVACActParamFreq_Reserved2" ;
    logical_value, 8, "HVACActParamFreq_Reserved3" ;
    logical_value, 9, "HVACActParamFreq_Reserved4" ;
    logical_value, 10, "HVACActParamFreq_Reserved5" ;
    logical_value, 11, "HVACActParamFreq_Reserved6" ;
    logical_value, 12, "HVACActParamFreq_Reserved7" ;
    logical_value, 13, "HVACActParamFreq_Reserved8" ;
    logical_value, 14, "HVACActParamFreq_Reserved9" ;
    logical_value, 15, "HVACActParamFreq_Invalid" ;
  }
  HVACAct4Cmd_ParamPosMode {
    logical_value, 0, "HVACActParamPosMode_SelectionOfFPOS" ;
    logical_value, 1, "HVACActParamPosMode_SelectionOfInitPOS" ;
    logical_value, 2, "HVACActParamPosMode_NoSelectedPosition" ;
    logical_value, 3, "HVACActParamPosMode_Invalid" ;
  }
  HVACAct5Cmd_ConfigDir {
    logical_value, 0, "HVACActConfigDir_MovermentsInCW" ;
    logical_value, 1, "HVACActConfigDir_MovementsInCCW" ;
    logical_value, 2, "HVACActConfigDir_NA1" ;
    logical_value, 3, "HVACActConfigDir_NA2" ;
  }
  HVACAct5Cmd_ConfigEmRun {
    logical_value, 0, "HVACActConfigEmRunCmd_EmergencyRunDisabled" ;
    logical_value, 1, "HVACActConfigEmRunCmd_EmergencyRunEnabled" ;
    logical_value, 2, "HVACActConfigEmRunCmd_NA1" ;
    logical_value, 3, "HVACActConfigEmRunCmd_NA2" ;
  }
  HVACAct5Cmd_ConfigEmRunDir {
    logical_value, 0, "HVACActConfigEmRunDir_EmergencyRunLowEndStop" ;
    logical_value, 1, "HVACActConfigEmRunDir_EmergencyRunHighEndStop" ;
    logical_value, 2, "HVACActConfigEmRunDir_NA1" ;
    logical_value, 3, "HVACActConfigEmRunDir_NA2" ;
  }
  HVACAct5Cmd_ConfigMode {
    logical_value, 0, "HVACActConfigMode_NormalMode" ;
    logical_value, 1, "HVACActConfigMode_StopMode" ;
    logical_value, 2, "HVACActConfigMode_NA1" ;
    logical_value, 3, "HVACActConfigMode_NA2" ;
  }
  HVACAct5Cmd_CtrlClearFlags {
    physical_value, 0, 15, 1, 0, "NotApplicable" ;
  }
  HVACAct5Cmd_CtrlLoadData {
    logical_value, 0, "HVACActCtrlLoadData_DoNotSaveInNVRAM" ;
    logical_value, 1, "HVACActCtrlLoadData_SaveDataInNVRAM" ;
    logical_value, 2, "HVACActCtrlLoadData_Reserved" ;
    logical_value, 3, "HVACActCtrlLoadData_Invalid" ;
  }
  HVACAct5Cmd_CtrlStallEn {
    logical_value, 0, "HVACActCtrlStallEn_Off" ;
    logical_value, 1, "HVACActCtrlStallEn_On" ;
    logical_value, 2, "HVACActCtrlStallEn_NA1" ;
    logical_value, 3, "HVACActCtrlStallEn_NA2" ;
  }
  HVACAct5Cmd_ParamCoils {
    logical_value, 0, "HVACActParamCoils_CoilsNotEnergizedWhenActStopped" ;
    logical_value, 1, "HVACActParamCoils_CoilsNEnergizedWhenActStopped" ;
    logical_value, 2, "HVACActParamCoils_Reserved" ;
    logical_value, 3, "HVACActParamCoils_Invalid" ;
  }
  HVACAct5Cmd_ParamFreq {
    logical_value, 0, "HVACActParamFreq_Stopped" ;
    logical_value, 1, "HVACActParamFreq_240_320sps" ;
    logical_value, 2, "HVACActParamFreq_320sps" ;
    logical_value, 3, "HVACActParamFreq_430sps" ;
    logical_value, 4, "HVACActParamFreq_540sps1" ;
    logical_value, 5, "HVACActParamFreq_540sps2" ;
    logical_value, 6, "HVACActParamFreq_Reserved1" ;
    logical_value, 7, "HVACActParamFreq_Reserved2" ;
    logical_value, 8, "HVACActParamFreq_Reserved3" ;
    logical_value, 9, "HVACActParamFreq_Reserved4" ;
    logical_value, 10, "HVACActParamFreq_Reserved5" ;
    logical_value, 11, "HVACActParamFreq_Reserved6" ;
    logical_value, 12, "HVACActParamFreq_Reserved7" ;
    logical_value, 13, "HVACActParamFreq_Reserved8" ;
    logical_value, 14, "HVACActParamFreq_Reserved9" ;
    logical_value, 15, "HVACActParamFreq_Invalid" ;
  }
  HVACAct5Cmd_ParamPosMode {
    logical_value, 0, "HVACActParamPosMode_SelectionOfFPOS" ;
    logical_value, 1, "HVACActParamPosMode_SelectionOfInitPOS" ;
    logical_value, 2, "HVACActParamPosMode_NoSelectedPosition" ;
    logical_value, 3, "HVACActParamPosMode_Invalid" ;
  }
  LIN_HVACAct1Stat_Conf2RunUpDir {
    logical_value, 0, "HVACActConf2RunUpDir_MovementGoingInSmallerPosition" ;
    logical_value, 1, "HVACActConf2RunUpDir_MovementGoingInBiggerPosition" ;
    logical_value, 2, "HVACActConf2RunUpDir_NoPreviousMovementPerformed" ;
    logical_value, 3, "HVACActConf2RunUpDir_FunctionNotImplemented" ;
  }
  LIN_HVACAct1Stat_Conf2SpecFnc {
    logical_value, 0, "HVACActConf2SpecFnc_NoSpecialFunctionImplemented" ;
    logical_value, 1, "HVACActConf2SpecFnc_SpecialFunctionImplemented" ;
    logical_value, 2, "HVACActConf2SpecFnc_Reserved" ;
    logical_value, 3, "HVACActConf2SpecFnc_FunctionNotImplemented" ;
  }
  LIN_HVACAct1Stat_Conf2TorqueVar {
    logical_value, 0, "HVACActConf2TorqueVar_MotorWithoutTorqueCurrentDisabled" ;
    logical_value, 1, "HVACActConf2TorqueVar_MotorHoldingTorqueCurrentDisabled" ;
    logical_value, 2, "HVACActConf2TorqueVar_Reserved" ;
    logical_value, 3, "HVACActConf2TorqueVar_FuntionNotImplemented" ;
  }
  LIN_HVACAct1Stat_ConfigDir {
    logical_value, 0, "HVACActConfigDir_MovermentsInCW" ;
    logical_value, 1, "HVACActConfigDir_MovementsInCCW" ;
    logical_value, 2, "HVACActConfigDir_NA1" ;
    logical_value, 3, "HVACActConfigDir_NA2" ;
  }
  LIN_HVACAct1Stat_ConfigEmRun {
    logical_value, 0, "HVACActConfigEmRunStat_EmergencyRun" ;
    logical_value, 1, "HVACActConfigEmRunStat_NoEmergencyRun" ;
    logical_value, 2, "HVACActConfigEmRunStat_NA1" ;
    logical_value, 3, "HVACActConfigEmRunStat_NA2" ;
  }
  LIN_HVACAct1Stat_ConfigEmRunDir {
    logical_value, 0, "HVACActConfigEmRunDir_EmergencyRunLowEndStop" ;
    logical_value, 1, "HVACActConfigEmRunDir_EmergencyRunHighEndStop" ;
    logical_value, 2, "HVACActConfigEmRunDir_NA1" ;
    logical_value, 3, "HVACActConfigEmRunDir_NA2" ;
  }
  LIN_HVACAct1Stat_ConfigMode {
    logical_value, 0, "HVACActConfigMode_NormalMode" ;
    logical_value, 1, "HVACActConfigMode_StopMode" ;
    logical_value, 2, "HVACActConfigMode_NA1" ;
    logical_value, 3, "HVACActConfigMode_NA2" ;
  }
  LIN_HVACAct1Stat_ErrorElectr {
    logical_value, 0, "HVACActErrorElectr_NoCoilsError" ;
    logical_value, 1, "HVACActErrorElectr_OpenLoadOrShortCircuit" ;
    logical_value, 2, "HVACActErrorElectr_FlashROMCorruption" ;
    logical_value, 3, "HVACActErrorElectr_Invalid" ;
  }
  LIN_HVACAct1Stat_ErrorSupply {
    logical_value, 0, "HVACActErrorSupply_PowerSupplyInDefinedRange" ;
    logical_value, 1, "HVACActErrorSupply_PowerSupplyUnderDefinedRange" ;
    logical_value, 2, "HVACActErrorSupply_PowerSupplyOverDefinedRange" ;
    logical_value, 3, "HVACActErrorSupply_Invalid" ;
  }
  LIN_HVACAct1Stat_ErrorTemp {
    logical_value, 0, "HVACActErrorTemp_NormalTemperature" ;
    logical_value, 1, "HVACActErrorTemp_OverTemperature" ;
    logical_value, 2, "HVACActErrorTemp_Reserved" ;
    logical_value, 3, "HVACActErrorTemp_Invalid" ;
  }
  LIN_HVACAct1Stat_ParamCoils {
    logical_value, 0, "HVACActParamCoils_CoilsNotEnergizedWhenActStopped" ;
    logical_value, 1, "HVACActParamCoils_CoilsNEnergizedWhenActStopped" ;
    logical_value, 2, "HVACActParamCoils_Reserved" ;
    logical_value, 3, "HVACActParamCoils_Invalid" ;
  }
  LIN_HVACAct1Stat_ParamFreq {
    logical_value, 0, "HVACActParamFreq_Stopped" ;
    logical_value, 1, "HVACActParamFreq_240_320sps" ;
    logical_value, 2, "HVACActParamFreq_320sps" ;
    logical_value, 3, "HVACActParamFreq_430sps" ;
    logical_value, 4, "HVACActParamFreq_540sps1" ;
    logical_value, 5, "HVACActParamFreq_540sps2" ;
    logical_value, 6, "HVACActParamFreq_Reserved1" ;
    logical_value, 7, "HVACActParamFreq_Reserved2" ;
    logical_value, 8, "HVACActParamFreq_Reserved3" ;
    logical_value, 9, "HVACActParamFreq_Reserved4" ;
    logical_value, 10, "HVACActParamFreq_Reserved5" ;
    logical_value, 11, "HVACActParamFreq_Reserved6" ;
    logical_value, 12, "HVACActParamFreq_Reserved7" ;
    logical_value, 13, "HVACActParamFreq_Reserved8" ;
    logical_value, 14, "HVACActParamFreq_Reserved9" ;
    logical_value, 15, "HVACActParamFreq_Invalid" ;
  }
  LIN_HVACAct1Stat_ParamPosMode {
    logical_value, 0, "HVACActParamPosMode_SelectionOfFPOS" ;
    logical_value, 1, "HVACActParamPosMode_SelectionOfInitPOS" ;
    logical_value, 2, "HVACActParamPosMode_NoSelectedPosition" ;
    logical_value, 3, "HVACActParamPosMode_Invalid" ;
  }
  LIN_HVACAct1Stat_StatusEmRun {
    logical_value, 0, "HVACActStatusEmRun_NoEmergencyRun" ;
    logical_value, 1, "HVACActStatusEmRun_EmergencyRunOccuredOrInProgress" ;
    logical_value, 2, "HVACActStatusEmRun_Reserved" ;
    logical_value, 3, "HVACActStatusEmRun_Invalid" ;
  }
  LIN_HVACAct1Stat_StatusReset {
    logical_value, 0, "HVACActStatusReset_NoReset" ;
    logical_value, 1, "HVACActStatusReset_Reset" ;
    logical_value, 2, "HVACActStatusReset_Reserved" ;
    logical_value, 3, "HVACActStatusReset_Invalid" ;
  }
  LIN_HVACAct1Stat_StatusStall {
    logical_value, 0, "HVACActStatusStall_NoEndStopDetected" ;
    logical_value, 1, "HVACActStatusStall_EndStopDetected" ;
    logical_value, 2, "HVACActStatusStall_Invalid1" ;
    logical_value, 3, "HVACActStatusStall_Invalid2" ;
  }
  LIN_HVACAct1Stat_StatusStallEn {
    logical_value, 0, "HVACActStatusStallEn_StallDetectionDisabled" ;
    logical_value, 1, "HVACActStatusStallEn_StallDetectionEnabled" ;
    logical_value, 2, "HVACActStatusStallEn_Reserved" ;
    logical_value, 3, "HVACActStatusStallEn_Invalid" ;
  }
  LIN_HVACAct2Stat_Conf2RunUpDir {
    logical_value, 0, "HVACActConf2RunUpDir_MovementGoingInSmallerPosition" ;
    logical_value, 1, "HVACActConf2RunUpDir_MovementGoingInBiggerPosition" ;
    logical_value, 2, "HVACActConf2RunUpDir_NoPreviousMovementPerformed" ;
    logical_value, 3, "HVACActConf2RunUpDir_FunctionNotImplemented" ;
  }
  LIN_HVACAct2Stat_Conf2SpecFnc {
    logical_value, 0, "HVACActConf2SpecFnc_NoSpecialFunctionImplemented" ;
    logical_value, 1, "HVACActConf2SpecFnc_SpecialFunctionImplemented" ;
    logical_value, 2, "HVACActConf2SpecFnc_Reserved" ;
    logical_value, 3, "HVACActConf2SpecFnc_FunctionNotImplemented" ;
  }
  LIN_HVACAct2Stat_Conf2TorqueVar {
    logical_value, 0, "HVACActConf2TorqueVar_MotorWithoutTorqueCurrentDisabled" ;
    logical_value, 1, "HVACActConf2TorqueVar_MotorHoldingTorqueCurrentDisabled" ;
    logical_value, 2, "HVACActConf2TorqueVar_Reserved" ;
    logical_value, 3, "HVACActConf2TorqueVar_FuntionNotImplemented" ;
  }
  LIN_HVACAct2Stat_ConfigDir {
    logical_value, 0, "HVACActConfigDir_MovermentsInCW" ;
    logical_value, 1, "HVACActConfigDir_MovementsInCCW" ;
    logical_value, 2, "HVACActConfigDir_NA1" ;
    logical_value, 3, "HVACActConfigDir_NA2" ;
  }
  LIN_HVACAct2Stat_ConfigEmRun {
    logical_value, 0, "HVACActConfigEmRunStat_EmergencyRun" ;
    logical_value, 1, "HVACActConfigEmRunStat_NoEmergencyRun" ;
    logical_value, 2, "HVACActConfigEmRunStat_NA1" ;
    logical_value, 3, "HVACActConfigEmRunStat_NA2" ;
  }
  LIN_HVACAct2Stat_ConfigEmRunDir {
    logical_value, 0, "HVACActConfigEmRunDir_EmergencyRunLowEndStop" ;
    logical_value, 1, "HVACActConfigEmRunDir_EmergencyRunHighEndStop" ;
    logical_value, 2, "HVACActConfigEmRunDir_NA1" ;
    logical_value, 3, "HVACActConfigEmRunDir_NA2" ;
  }
  LIN_HVACAct2Stat_ConfigMode {
    logical_value, 0, "HVACActConfigMode_NormalMode" ;
    logical_value, 1, "HVACActConfigMode_StopMode" ;
    logical_value, 2, "HVACActConfigMode_NA1" ;
    logical_value, 3, "HVACActConfigMode_NA2" ;
  }
  LIN_HVACAct2Stat_ErrorElectr {
    logical_value, 0, "HVACActErrorElectr_NoCoilsError" ;
    logical_value, 1, "HVACActErrorElectr_OpenLoadOrShortCircuit" ;
    logical_value, 2, "HVACActErrorElectr_FlashROMCorruption" ;
    logical_value, 3, "HVACActErrorElectr_Invalid" ;
  }
  LIN_HVACAct2Stat_ErrorSupply {
    logical_value, 0, "HVACActErrorSupply_PowerSupplyInDefinedRange" ;
    logical_value, 1, "HVACActErrorSupply_PowerSupplyUnderDefinedRange" ;
    logical_value, 2, "HVACActErrorSupply_PowerSupplyOverDefinedRange" ;
    logical_value, 3, "HVACActErrorSupply_Invalid" ;
  }
  LIN_HVACAct2Stat_ErrorTemp {
    logical_value, 0, "HVACActErrorTemp_NormalTemperature" ;
    logical_value, 1, "HVACActErrorTemp_OverTemperature" ;
    logical_value, 2, "HVACActErrorTemp_Reserved" ;
    logical_value, 3, "HVACActErrorTemp_Invalid" ;
  }
  LIN_HVACAct2Stat_ParamCoils {
    logical_value, 0, "HVACActParamCoils_CoilsNotEnergizedWhenActStopped" ;
    logical_value, 1, "HVACActParamCoils_CoilsNEnergizedWhenActStopped" ;
    logical_value, 2, "HVACActParamCoils_Reserved" ;
    logical_value, 3, "HVACActParamCoils_Invalid" ;
  }
  LIN_HVACAct2Stat_ParamFreq {
    logical_value, 0, "HVACActParamFreq_Stopped" ;
    logical_value, 1, "HVACActParamFreq_240_320sps" ;
    logical_value, 2, "HVACActParamFreq_320sps" ;
    logical_value, 3, "HVACActParamFreq_430sps" ;
    logical_value, 4, "HVACActParamFreq_540sps1" ;
    logical_value, 5, "HVACActParamFreq_540sps2" ;
    logical_value, 6, "HVACActParamFreq_Reserved1" ;
    logical_value, 7, "HVACActParamFreq_Reserved2" ;
    logical_value, 8, "HVACActParamFreq_Reserved3" ;
    logical_value, 9, "HVACActParamFreq_Reserved4" ;
    logical_value, 10, "HVACActParamFreq_Reserved5" ;
    logical_value, 11, "HVACActParamFreq_Reserved6" ;
    logical_value, 12, "HVACActParamFreq_Reserved7" ;
    logical_value, 13, "HVACActParamFreq_Reserved8" ;
    logical_value, 14, "HVACActParamFreq_Reserved9" ;
    logical_value, 15, "HVACActParamFreq_Invalid" ;
  }
  LIN_HVACAct2Stat_ParamPosMode {
    logical_value, 0, "HVACActParamPosMode_SelectionOfFPOS" ;
    logical_value, 1, "HVACActParamPosMode_SelectionOfInitPOS" ;
    logical_value, 2, "HVACActParamPosMode_NoSelectedPosition" ;
    logical_value, 3, "HVACActParamPosMode_Invalid" ;
  }
  LIN_HVACAct2Stat_StatusEmRun {
    logical_value, 0, "HVACActStatusEmRun_NoEmergencyRun" ;
    logical_value, 1, "HVACActStatusEmRun_EmergencyRunOccuredOrInProgress" ;
    logical_value, 2, "HVACActStatusEmRun_Reserved" ;
    logical_value, 3, "HVACActStatusEmRun_Invalid" ;
  }
  LIN_HVACAct2Stat_StatusReset {
    logical_value, 0, "HVACActStatusReset_NoReset" ;
    logical_value, 1, "HVACActStatusReset_Reset" ;
    logical_value, 2, "HVACActStatusReset_Reserved" ;
    logical_value, 3, "HVACActStatusReset_Invalid" ;
  }
  LIN_HVACAct2Stat_StatusStall {
    logical_value, 0, "HVACActStatusStall_NoEndStopDetected" ;
    logical_value, 1, "HVACActStatusStall_EndStopDetected" ;
    logical_value, 2, "HVACActStatusStall_Invalid1" ;
    logical_value, 3, "HVACActStatusStall_Invalid2" ;
  }
  LIN_HVACAct2Stat_StatusStallEn {
    logical_value, 0, "HVACActStatusStallEn_StallDetectionDisabled" ;
    logical_value, 1, "HVACActStatusStallEn_StallDetectionEnabled" ;
    logical_value, 2, "HVACActStatusStallEn_Reserved" ;
    logical_value, 3, "HVACActStatusStallEn_Invalid" ;
  }
  LIN_HVACAct3Stat_Conf2RunUpDir {
    logical_value, 0, "HVACActConf2RunUpDir_MovementGoingInSmallerPosition" ;
    logical_value, 1, "HVACActConf2RunUpDir_MovementGoingInBiggerPosition" ;
    logical_value, 2, "HVACActConf2RunUpDir_NoPreviousMovementPerformed" ;
    logical_value, 3, "HVACActConf2RunUpDir_FunctionNotImplemented" ;
  }
  LIN_HVACAct3Stat_Conf2SpecFnc {
    logical_value, 0, "HVACActConf2SpecFnc_NoSpecialFunctionImplemented" ;
    logical_value, 1, "HVACActConf2SpecFnc_SpecialFunctionImplemented" ;
    logical_value, 2, "HVACActConf2SpecFnc_Reserved" ;
    logical_value, 3, "HVACActConf2SpecFnc_FunctionNotImplemented" ;
  }
  LIN_HVACAct3Stat_Conf2TorqueVar {
    logical_value, 0, "HVACActConf2TorqueVar_MotorWithoutTorqueCurrentDisabled" ;
    logical_value, 1, "HVACActConf2TorqueVar_MotorHoldingTorqueCurrentDisabled" ;
    logical_value, 2, "HVACActConf2TorqueVar_Reserved" ;
    logical_value, 3, "HVACActConf2TorqueVar_FuntionNotImplemented" ;
  }
  LIN_HVACAct3Stat_ConfigDir {
    logical_value, 0, "HVACActConfigDir_MovermentsInCW" ;
    logical_value, 1, "HVACActConfigDir_MovementsInCCW" ;
    logical_value, 2, "HVACActConfigDir_NA1" ;
    logical_value, 3, "HVACActConfigDir_NA2" ;
  }
  LIN_HVACAct3Stat_ConfigEmRun {
    logical_value, 0, "HVACActConfigEmRunStat_EmergencyRun" ;
    logical_value, 1, "HVACActConfigEmRunStat_NoEmergencyRun" ;
    logical_value, 2, "HVACActConfigEmRunStat_NA1" ;
    logical_value, 3, "HVACActConfigEmRunStat_NA2" ;
  }
  LIN_HVACAct3Stat_ConfigEmRunDir {
    logical_value, 0, "HVACActConfigEmRunDir_EmergencyRunLowEndStop" ;
    logical_value, 1, "HVACActConfigEmRunDir_EmergencyRunHighEndStop" ;
    logical_value, 2, "HVACActConfigEmRunDir_NA1" ;
    logical_value, 3, "HVACActConfigEmRunDir_NA2" ;
  }
  LIN_HVACAct3Stat_ConfigMode {
    logical_value, 0, "HVACActConfigMode_NormalMode" ;
    logical_value, 1, "HVACActConfigMode_StopMode" ;
    logical_value, 2, "HVACActConfigMode_NA1" ;
    logical_value, 3, "HVACActConfigMode_NA2" ;
  }
  LIN_HVACAct3Stat_ErrorElectr {
    logical_value, 0, "HVACActErrorElectr_NoCoilsError" ;
    logical_value, 1, "HVACActErrorElectr_OpenLoadOrShortCircuit" ;
    logical_value, 2, "HVACActErrorElectr_FlashROMCorruption" ;
    logical_value, 3, "HVACActErrorElectr_Invalid" ;
  }
  LIN_HVACAct3Stat_ErrorSupply {
    logical_value, 0, "HVACActErrorSupply_PowerSupplyInDefinedRange" ;
    logical_value, 1, "HVACActErrorSupply_PowerSupplyUnderDefinedRange" ;
    logical_value, 2, "HVACActErrorSupply_PowerSupplyOverDefinedRange" ;
    logical_value, 3, "HVACActErrorSupply_Invalid" ;
  }
  LIN_HVACAct3Stat_ErrorTemp {
    logical_value, 0, "HVACActErrorTemp_NormalTemperature" ;
    logical_value, 1, "HVACActErrorTemp_OverTemperature" ;
    logical_value, 2, "HVACActErrorTemp_Reserved" ;
    logical_value, 3, "HVACActErrorTemp_Invalid" ;
  }
  LIN_HVACAct3Stat_ParamCoils {
    logical_value, 0, "HVACActParamCoils_CoilsNotEnergizedWhenActStopped" ;
    logical_value, 1, "HVACActParamCoils_CoilsNEnergizedWhenActStopped" ;
    logical_value, 2, "HVACActParamCoils_Reserved" ;
    logical_value, 3, "HVACActParamCoils_Invalid" ;
  }
  LIN_HVACAct3Stat_ParamFreq {
    logical_value, 0, "HVACActParamFreq_Stopped" ;
    logical_value, 1, "HVACActParamFreq_240_320sps" ;
    logical_value, 2, "HVACActParamFreq_320sps" ;
    logical_value, 3, "HVACActParamFreq_430sps" ;
    logical_value, 4, "HVACActParamFreq_540sps1" ;
    logical_value, 5, "HVACActParamFreq_540sps2" ;
    logical_value, 6, "HVACActParamFreq_Reserved1" ;
    logical_value, 7, "HVACActParamFreq_Reserved2" ;
    logical_value, 8, "HVACActParamFreq_Reserved3" ;
    logical_value, 9, "HVACActParamFreq_Reserved4" ;
    logical_value, 10, "HVACActParamFreq_Reserved5" ;
    logical_value, 11, "HVACActParamFreq_Reserved6" ;
    logical_value, 12, "HVACActParamFreq_Reserved7" ;
    logical_value, 13, "HVACActParamFreq_Reserved8" ;
    logical_value, 14, "HVACActParamFreq_Reserved9" ;
    logical_value, 15, "HVACActParamFreq_Invalid" ;
  }
  LIN_HVACAct3Stat_ParamPosMode {
    logical_value, 0, "HVACActParamPosMode_SelectionOfFPOS" ;
    logical_value, 1, "HVACActParamPosMode_SelectionOfInitPOS" ;
    logical_value, 2, "HVACActParamPosMode_NoSelectedPosition" ;
    logical_value, 3, "HVACActParamPosMode_Invalid" ;
  }
  LIN_HVACAct3Stat_StatusEmRun {
    logical_value, 0, "HVACActStatusEmRun_NoEmergencyRun" ;
    logical_value, 1, "HVACActStatusEmRun_EmergencyRunOccuredOrInProgress" ;
    logical_value, 2, "HVACActStatusEmRun_Reserved" ;
    logical_value, 3, "HVACActStatusEmRun_Invalid" ;
  }
  LIN_HVACAct3Stat_StatusReset {
    logical_value, 0, "HVACActStatusReset_NoReset" ;
    logical_value, 1, "HVACActStatusReset_Reset" ;
    logical_value, 2, "HVACActStatusReset_Reserved" ;
    logical_value, 3, "HVACActStatusReset_Invalid" ;
  }
  LIN_HVACAct3Stat_StatusStall {
    logical_value, 0, "HVACActStatusStall_NoEndStopDetected" ;
    logical_value, 1, "HVACActStatusStall_EndStopDetected" ;
    logical_value, 2, "HVACActStatusStall_Invalid1" ;
    logical_value, 3, "HVACActStatusStall_Invalid2" ;
  }
  LIN_HVACAct3Stat_StatusStallEn {
    logical_value, 0, "HVACActStatusStallEn_StallDetectionDisabled" ;
    logical_value, 1, "HVACActStatusStallEn_StallDetectionEnabled" ;
    logical_value, 2, "HVACActStatusStallEn_Reserved" ;
    logical_value, 3, "HVACActStatusStallEn_Invalid" ;
  }
  LIN_HVACAct4Stat_Conf2RunUpDir {
    logical_value, 0, "HVACActConf2RunUpDir_MovementGoingInSmallerPosition" ;
    logical_value, 1, "HVACActConf2RunUpDir_MovementGoingInBiggerPosition" ;
    logical_value, 2, "HVACActConf2RunUpDir_NoPreviousMovementPerformed" ;
    logical_value, 3, "HVACActConf2RunUpDir_FunctionNotImplemented" ;
  }
  LIN_HVACAct4Stat_Conf2SpecFnc {
    logical_value, 0, "HVACActConf2SpecFnc_NoSpecialFunctionImplemented" ;
    logical_value, 1, "HVACActConf2SpecFnc_SpecialFunctionImplemented" ;
    logical_value, 2, "HVACActConf2SpecFnc_Reserved" ;
    logical_value, 3, "HVACActConf2SpecFnc_FunctionNotImplemented" ;
  }
  LIN_HVACAct4Stat_Conf2TorqueVar {
    logical_value, 0, "HVACActConf2TorqueVar_MotorWithoutTorqueCurrentDisabled" ;
    logical_value, 1, "HVACActConf2TorqueVar_MotorHoldingTorqueCurrentDisabled" ;
    logical_value, 2, "HVACActConf2TorqueVar_Reserved" ;
    logical_value, 3, "HVACActConf2TorqueVar_FuntionNotImplemented" ;
  }
  LIN_HVACAct4Stat_ConfigDir {
    logical_value, 0, "HVACActConfigDir_MovermentsInCW" ;
    logical_value, 1, "HVACActConfigDir_MovementsInCCW" ;
    logical_value, 2, "HVACActConfigDir_NA1" ;
    logical_value, 3, "HVACActConfigDir_NA2" ;
  }
  LIN_HVACAct4Stat_ConfigEmRun {
    logical_value, 0, "HVACActConfigEmRunStat_EmergencyRun" ;
    logical_value, 1, "HVACActConfigEmRunStat_NoEmergencyRun" ;
    logical_value, 2, "HVACActConfigEmRunStat_NA1" ;
    logical_value, 3, "HVACActConfigEmRunStat_NA2" ;
  }
  LIN_HVACAct4Stat_ConfigEmRunDir {
    logical_value, 0, "HVACActConfigEmRunDir_EmergencyRunLowEndStop" ;
    logical_value, 1, "HVACActConfigEmRunDir_EmergencyRunHighEndStop" ;
    logical_value, 2, "HVACActConfigEmRunDir_NA1" ;
    logical_value, 3, "HVACActConfigEmRunDir_NA2" ;
  }
  LIN_HVACAct4Stat_ConfigMode {
    logical_value, 0, "HVACActConfigMode_NormalMode" ;
    logical_value, 1, "HVACActConfigMode_StopMode" ;
    logical_value, 2, "HVACActConfigMode_NA1" ;
    logical_value, 3, "HVACActConfigMode_NA2" ;
  }
  LIN_HVACAct4Stat_ErrorElectr {
    logical_value, 0, "HVACActErrorElectr_NoCoilsError" ;
    logical_value, 1, "HVACActErrorElectr_OpenLoadOrShortCircuit" ;
    logical_value, 2, "HVACActErrorElectr_FlashROMCorruption" ;
    logical_value, 3, "HVACActErrorElectr_Invalid" ;
  }
  LIN_HVACAct4Stat_ErrorSupply {
    logical_value, 0, "HVACActErrorSupply_PowerSupplyInDefinedRange" ;
    logical_value, 1, "HVACActErrorSupply_PowerSupplyUnderDefinedRange" ;
    logical_value, 2, "HVACActErrorSupply_PowerSupplyOverDefinedRange" ;
    logical_value, 3, "HVACActErrorSupply_Invalid" ;
  }
  LIN_HVACAct4Stat_ErrorTemp {
    logical_value, 0, "HVACActErrorTemp_NormalTemperature" ;
    logical_value, 1, "HVACActErrorTemp_OverTemperature" ;
    logical_value, 2, "HVACActErrorTemp_Reserved" ;
    logical_value, 3, "HVACActErrorTemp_Invalid" ;
  }
  LIN_HVACAct4Stat_ParamCoils {
    logical_value, 0, "HVACActParamCoils_CoilsNotEnergizedWhenActStopped" ;
    logical_value, 1, "HVACActParamCoils_CoilsNEnergizedWhenActStopped" ;
    logical_value, 2, "HVACActParamCoils_Reserved" ;
    logical_value, 3, "HVACActParamCoils_Invalid" ;
  }
  LIN_HVACAct4Stat_ParamFreq {
    logical_value, 0, "HVACActParamFreq_Stopped" ;
    logical_value, 1, "HVACActParamFreq_240_320sps" ;
    logical_value, 2, "HVACActParamFreq_320sps" ;
    logical_value, 3, "HVACActParamFreq_430sps" ;
    logical_value, 4, "HVACActParamFreq_540sps1" ;
    logical_value, 5, "HVACActParamFreq_540sps2" ;
    logical_value, 6, "HVACActParamFreq_Reserved1" ;
    logical_value, 7, "HVACActParamFreq_Reserved2" ;
    logical_value, 8, "HVACActParamFreq_Reserved3" ;
    logical_value, 9, "HVACActParamFreq_Reserved4" ;
    logical_value, 10, "HVACActParamFreq_Reserved5" ;
    logical_value, 11, "HVACActParamFreq_Reserved6" ;
    logical_value, 12, "HVACActParamFreq_Reserved7" ;
    logical_value, 13, "HVACActParamFreq_Reserved8" ;
    logical_value, 14, "HVACActParamFreq_Reserved9" ;
    logical_value, 15, "HVACActParamFreq_Invalid" ;
  }
  LIN_HVACAct4Stat_ParamPosMode {
    logical_value, 0, "HVACActParamPosMode_SelectionOfFPOS" ;
    logical_value, 1, "HVACActParamPosMode_SelectionOfInitPOS" ;
    logical_value, 2, "HVACActParamPosMode_NoSelectedPosition" ;
    logical_value, 3, "HVACActParamPosMode_Invalid" ;
  }
  LIN_HVACAct4Stat_StatusEmRun {
    logical_value, 0, "HVACActStatusEmRun_NoEmergencyRun" ;
    logical_value, 1, "HVACActStatusEmRun_EmergencyRunOccuredOrInProgress" ;
    logical_value, 2, "HVACActStatusEmRun_Reserved" ;
    logical_value, 3, "HVACActStatusEmRun_Invalid" ;
  }
  LIN_HVACAct4Stat_StatusReset {
    logical_value, 0, "HVACActStatusReset_NoReset" ;
    logical_value, 1, "HVACActStatusReset_Reset" ;
    logical_value, 2, "HVACActStatusReset_Reserved" ;
    logical_value, 3, "HVACActStatusReset_Invalid" ;
  }
  LIN_HVACAct4Stat_StatusStall {
    logical_value, 0, "HVACActStatusStall_NoEndStopDetected" ;
    logical_value, 1, "HVACActStatusStall_EndStopDetected" ;
    logical_value, 2, "HVACActStatusStall_Invalid1" ;
    logical_value, 3, "HVACActStatusStall_Invalid2" ;
  }
  LIN_HVACAct4Stat_StatusStallEn {
    logical_value, 0, "HVACActStatusStallEn_StallDetectionDisabled" ;
    logical_value, 1, "HVACActStatusStallEn_StallDetectionEnabled" ;
    logical_value, 2, "HVACActStatusStallEn_Reserved" ;
    logical_value, 3, "HVACActStatusStallEn_Invalid" ;
  }
  LIN_HVACAct5Stat_Conf2RunUpDir {
    logical_value, 0, "HVACActConf2RunUpDir_MovementGoingInSmallerPosition" ;
    logical_value, 1, "HVACActConf2RunUpDir_MovementGoingInBiggerPosition" ;
    logical_value, 2, "HVACActConf2RunUpDir_NoPreviousMovementPerformed" ;
    logical_value, 3, "HVACActConf2RunUpDir_FunctionNotImplemented" ;
  }
  LIN_HVACAct5Stat_Conf2SpecFnc {
    logical_value, 0, "HVACActConf2SpecFnc_NoSpecialFunctionImplemented" ;
    logical_value, 1, "HVACActConf2SpecFnc_SpecialFunctionImplemented" ;
    logical_value, 2, "HVACActConf2SpecFnc_Reserved" ;
    logical_value, 3, "HVACActConf2SpecFnc_FunctionNotImplemented" ;
  }
  LIN_HVACAct5Stat_Conf2TorqueVar {
    logical_value, 0, "HVACActConf2TorqueVar_MotorWithoutTorqueCurrentDisabled" ;
    logical_value, 1, "HVACActConf2TorqueVar_MotorHoldingTorqueCurrentDisabled" ;
    logical_value, 2, "HVACActConf2TorqueVar_Reserved" ;
    logical_value, 3, "HVACActConf2TorqueVar_FuntionNotImplemented" ;
  }
  LIN_HVACAct5Stat_ConfigDir {
    logical_value, 0, "HVACActConfigDir_MovermentsInCW" ;
    logical_value, 1, "HVACActConfigDir_MovementsInCCW" ;
    logical_value, 2, "HVACActConfigDir_NA1" ;
    logical_value, 3, "HVACActConfigDir_NA2" ;
  }
  LIN_HVACAct5Stat_ConfigEmRun {
    logical_value, 0, "HVACActConfigEmRunStat_EmergencyRun" ;
    logical_value, 1, "HVACActConfigEmRunStat_NoEmergencyRun" ;
    logical_value, 2, "HVACActConfigEmRunStat_NA1" ;
    logical_value, 3, "HVACActConfigEmRunStat_NA2" ;
  }
  LIN_HVACAct5Stat_ConfigEmRunDir {
    logical_value, 0, "HVACActConfigEmRunDir_EmergencyRunLowEndStop" ;
    logical_value, 1, "HVACActConfigEmRunDir_EmergencyRunHighEndStop" ;
    logical_value, 2, "HVACActConfigEmRunDir_NA1" ;
    logical_value, 3, "HVACActConfigEmRunDir_NA2" ;
  }
  LIN_HVACAct5Stat_ConfigMode {
    logical_value, 0, "HVACActConfigMode_NormalMode" ;
    logical_value, 1, "HVACActConfigMode_StopMode" ;
    logical_value, 2, "HVACActConfigMode_NA1" ;
    logical_value, 3, "HVACActConfigMode_NA2" ;
  }
  LIN_HVACAct5Stat_ErrorElectr {
    logical_value, 0, "HVACActErrorElectr_NoCoilsError" ;
    logical_value, 1, "HVACActErrorElectr_OpenLoadOrShortCircuit" ;
    logical_value, 2, "HVACActErrorElectr_FlashROMCorruption" ;
    logical_value, 3, "HVACActErrorElectr_Invalid" ;
  }
  LIN_HVACAct5Stat_ErrorSupply {
    logical_value, 0, "HVACActErrorSupply_PowerSupplyInDefinedRange" ;
    logical_value, 1, "HVACActErrorSupply_PowerSupplyUnderDefinedRange" ;
    logical_value, 2, "HVACActErrorSupply_PowerSupplyOverDefinedRange" ;
    logical_value, 3, "HVACActErrorSupply_Invalid" ;
  }
  LIN_HVACAct5Stat_ErrorTemp {
    logical_value, 0, "HVACActErrorTemp_NormalTemperature" ;
    logical_value, 1, "HVACActErrorTemp_OverTemperature" ;
    logical_value, 2, "HVACActErrorTemp_Reserved" ;
    logical_value, 3, "HVACActErrorTemp_Invalid" ;
  }
  LIN_HVACAct5Stat_ParamCoils {
    logical_value, 0, "HVACActParamCoils_CoilsNotEnergizedWhenActStopped" ;
    logical_value, 1, "HVACActParamCoils_CoilsNEnergizedWhenActStopped" ;
    logical_value, 2, "HVACActParamCoils_Reserved" ;
    logical_value, 3, "HVACActParamCoils_Invalid" ;
  }
  LIN_HVACAct5Stat_ParamFreq {
    logical_value, 0, "HVACActParamFreq_Stopped" ;
    logical_value, 1, "HVACActParamFreq_240_320sps" ;
    logical_value, 2, "HVACActParamFreq_320sps" ;
    logical_value, 3, "HVACActParamFreq_430sps" ;
    logical_value, 4, "HVACActParamFreq_540sps1" ;
    logical_value, 5, "HVACActParamFreq_540sps2" ;
    logical_value, 6, "HVACActParamFreq_Reserved1" ;
    logical_value, 7, "HVACActParamFreq_Reserved2" ;
    logical_value, 8, "HVACActParamFreq_Reserved3" ;
    logical_value, 9, "HVACActParamFreq_Reserved4" ;
    logical_value, 10, "HVACActParamFreq_Reserved5" ;
    logical_value, 11, "HVACActParamFreq_Reserved6" ;
    logical_value, 12, "HVACActParamFreq_Reserved7" ;
    logical_value, 13, "HVACActParamFreq_Reserved8" ;
    logical_value, 14, "HVACActParamFreq_Reserved9" ;
    logical_value, 15, "HVACActParamFreq_Invalid" ;
  }
  LIN_HVACAct5Stat_ParamPosMode {
    logical_value, 0, "HVACActParamPosMode_SelectionOfFPOS" ;
    logical_value, 1, "HVACActParamPosMode_SelectionOfInitPOS" ;
    logical_value, 2, "HVACActParamPosMode_NoSelectedPosition" ;
    logical_value, 3, "HVACActParamPosMode_Invalid" ;
  }
  LIN_HVACAct5Stat_StatusEmRun {
    logical_value, 0, "HVACActStatusEmRun_NoEmergencyRun" ;
    logical_value, 1, "HVACActStatusEmRun_EmergencyRunOccuredOrInProgress" ;
    logical_value, 2, "HVACActStatusEmRun_Reserved" ;
    logical_value, 3, "HVACActStatusEmRun_Invalid" ;
  }
  LIN_HVACAct5Stat_StatusReset {
    logical_value, 0, "HVACActStatusReset_NoReset" ;
    logical_value, 1, "HVACActStatusReset_Reset" ;
    logical_value, 2, "HVACActStatusReset_Reserved" ;
    logical_value, 3, "HVACActStatusReset_Invalid" ;
  }
  LIN_HVACAct5Stat_StatusStall {
    logical_value, 0, "HVACActStatusStall_NoEndStopDetected" ;
    logical_value, 1, "HVACActStatusStall_EndStopDetected" ;
    logical_value, 2, "HVACActStatusStall_Invalid1" ;
    logical_value, 3, "HVACActStatusStall_Invalid2" ;
  }
  LIN_HVACAct5Stat_StatusStallEn {
    logical_value, 0, "HVACActStatusStallEn_StallDetectionDisabled" ;
    logical_value, 1, "HVACActStatusStallEn_StallDetectionEnabled" ;
    logical_value, 2, "HVACActStatusStallEn_Reserved" ;
    logical_value, 3, "HVACActStatusStallEn_Invalid" ;
  }
}

Signal_representation {
  HVACAct1Cmd_ConfigDir: HVACAct1Cmd_ConfigDir ;
  HVACAct1Cmd_ConfigEmRun: HVACAct1Cmd_ConfigEmRun ;
  HVACAct1Cmd_ConfigEmRunDir: HVACAct1Cmd_ConfigEmRunDir ;
  HVACAct1Cmd_ConfigMode: HVACAct1Cmd_ConfigMode ;
  HVACAct1Cmd_CtrlClearFlags: HVACAct1Cmd_CtrlClearFlags ;
  HVACAct1Cmd_CtrlLoadData: HVACAct1Cmd_CtrlLoadData ;
  HVACAct1Cmd_CtrlStallEn: HVACAct1Cmd_CtrlStallEn ;
  HVACAct1Cmd_ParamCoils: HVACAct1Cmd_ParamCoils ;
  HVACAct1Cmd_ParamFreq: HVACAct1Cmd_ParamFreq ;
  HVACAct1Cmd_ParamPosMode: HVACAct1Cmd_ParamPosMode ;
  HVACAct2Cmd_ConfigDir: HVACAct2Cmd_ConfigDir ;
  HVACAct2Cmd_ConfigEmRun: HVACAct2Cmd_ConfigEmRun ;
  HVACAct2Cmd_ConfigEmRunDir: HVACAct2Cmd_ConfigEmRunDir ;
  HVACAct2Cmd_ConfigMode: HVACAct2Cmd_ConfigMode ;
  HVACAct2Cmd_CtrlClearFlags: HVACAct2Cmd_CtrlClearFlags ;
  HVACAct2Cmd_CtrlLoadData: HVACAct2Cmd_CtrlLoadData ;
  HVACAct2Cmd_CtrlStallEn: HVACAct2Cmd_CtrlStallEn ;
  HVACAct2Cmd_ParamCoils: HVACAct2Cmd_ParamCoils ;
  HVACAct2Cmd_ParamFreq: HVACAct2Cmd_ParamFreq ;
  HVACAct2Cmd_ParamPosMode: HVACAct2Cmd_ParamPosMode ;
  HVACAct3Cmd_ConfigDir: HVACAct3Cmd_ConfigDir ;
  HVACAct3Cmd_ConfigEmRun: HVACAct3Cmd_ConfigEmRun ;
  HVACAct3Cmd_ConfigEmRunDir: HVACAct3Cmd_ConfigEmRunDir ;
  HVACAct3Cmd_ConfigMode: HVACAct3Cmd_ConfigMode ;
  HVACAct3Cmd_CtrlClearFlags: HVACAct3Cmd_CtrlClearFlags ;
  HVACAct3Cmd_CtrlLoadData: HVACAct3Cmd_CtrlLoadData ;
  HVACAct3Cmd_CtrlStallEn: HVACAct3Cmd_CtrlStallEn ;
  HVACAct3Cmd_ParamCoils: HVACAct3Cmd_ParamCoils ;
  HVACAct3Cmd_ParamFreq: HVACAct3Cmd_ParamFreq ;
  HVACAct3Cmd_ParamPosMode: HVACAct3Cmd_ParamPosMode ;
  HVACAct4Cmd_ConfigDir: HVACAct4Cmd_ConfigDir ;
  HVACAct4Cmd_ConfigEmRun: HVACAct4Cmd_ConfigEmRun ;
  HVACAct4Cmd_ConfigEmRunDir: HVACAct4Cmd_ConfigEmRunDir ;
  HVACAct4Cmd_ConfigMode: HVACAct4Cmd_ConfigMode ;
  HVACAct4Cmd_CtrlClearFlags: HVACAct4Cmd_CtrlClearFlags ;
  HVACAct4Cmd_CtrlLoadData: HVACAct4Cmd_CtrlLoadData ;
  HVACAct4Cmd_CtrlStallEn: HVACAct4Cmd_CtrlStallEn ;
  HVACAct4Cmd_ParamCoils: HVACAct4Cmd_ParamCoils ;
  HVACAct4Cmd_ParamFreq: HVACAct4Cmd_ParamFreq ;
  HVACAct4Cmd_ParamPosMode: HVACAct4Cmd_ParamPosMode ;
  HVACAct5Cmd_ConfigDir: HVACAct5Cmd_ConfigDir ;
  HVACAct5Cmd_ConfigEmRun: HVACAct5Cmd_ConfigEmRun ;
  HVACAct5Cmd_ConfigEmRunDir: HVACAct5Cmd_ConfigEmRunDir ;
  HVACAct5Cmd_ConfigMode: HVACAct5Cmd_ConfigMode ;
  HVACAct5Cmd_CtrlClearFlags: HVACAct5Cmd_CtrlClearFlags ;
  HVACAct5Cmd_CtrlLoadData: HVACAct5Cmd_CtrlLoadData ;
  HVACAct5Cmd_CtrlStallEn: HVACAct5Cmd_CtrlStallEn ;
  HVACAct5Cmd_ParamCoils: HVACAct5Cmd_ParamCoils ;
  HVACAct5Cmd_ParamFreq: HVACAct5Cmd_ParamFreq ;
  HVACAct5Cmd_ParamPosMode: HVACAct5Cmd_ParamPosMode ;
  LIN_HVACAct1Stat_Conf2RunUpDir: LIN_HVACAct1Stat_Conf2RunUpDir ;
  LIN_HVACAct1Stat_Conf2SpecFnc: LIN_HVACAct1Stat_Conf2SpecFnc ;
  LIN_HVACAct1Stat_Conf2TorqueVar: LIN_HVACAct1Stat_Conf2TorqueVar ;
  LIN_HVACAct1Stat_ConfigDir: LIN_HVACAct1Stat_ConfigDir ;
  LIN_HVACAct1Stat_ConfigEmRun: LIN_HVACAct1Stat_ConfigEmRun ;
  LIN_HVACAct1Stat_ConfigEmRunDir: LIN_HVACAct1Stat_ConfigEmRunDir ;
  LIN_HVACAct1Stat_ConfigMode: LIN_HVACAct1Stat_ConfigMode ;
  LIN_HVACAct1Stat_ErrorElectr: LIN_HVACAct1Stat_ErrorElectr ;
  LIN_HVACAct1Stat_ErrorSupply: LIN_HVACAct1Stat_ErrorSupply ;
  LIN_HVACAct1Stat_ErrorTemp: LIN_HVACAct1Stat_ErrorTemp ;
  LIN_HVACAct1Stat_ParamCoils: LIN_HVACAct1Stat_ParamCoils ;
  LIN_HVACAct1Stat_ParamFreq: LIN_HVACAct1Stat_ParamFreq ;
  LIN_HVACAct1Stat_ParamPosMode: LIN_HVACAct1Stat_ParamPosMode ;
  LIN_HVACAct1Stat_StatusEmRun: LIN_HVACAct1Stat_StatusEmRun ;
  LIN_HVACAct1Stat_StatusReset: LIN_HVACAct1Stat_StatusReset ;
  LIN_HVACAct1Stat_StatusStall: LIN_HVACAct1Stat_StatusStall ;
  LIN_HVACAct1Stat_StatusStallEn: LIN_HVACAct1Stat_StatusStallEn ;
  LIN_HVACAct2Stat_Conf2RunUpDir: LIN_HVACAct2Stat_Conf2RunUpDir ;
  LIN_HVACAct2Stat_Conf2SpecFnc: LIN_HVACAct2Stat_Conf2SpecFnc ;
  LIN_HVACAct2Stat_Conf2TorqueVar: LIN_HVACAct2Stat_Conf2TorqueVar ;
  LIN_HVACAct2Stat_ConfigDir: LIN_HVACAct2Stat_ConfigDir ;
  LIN_HVACAct2Stat_ConfigEmRun: LIN_HVACAct2Stat_ConfigEmRun ;
  LIN_HVACAct2Stat_ConfigEmRunDir: LIN_HVACAct2Stat_ConfigEmRunDir ;
  LIN_HVACAct2Stat_ConfigMode: LIN_HVACAct2Stat_ConfigMode ;
  LIN_HVACAct2Stat_ErrorElectr: LIN_HVACAct2Stat_ErrorElectr ;
  LIN_HVACAct2Stat_ErrorSupply: LIN_HVACAct2Stat_ErrorSupply ;
  LIN_HVACAct2Stat_ErrorTemp: LIN_HVACAct2Stat_ErrorTemp ;
  LIN_HVACAct2Stat_ParamCoils: LIN_HVACAct2Stat_ParamCoils ;
  LIN_HVACAct2Stat_ParamFreq: LIN_HVACAct2Stat_ParamFreq ;
  LIN_HVACAct2Stat_ParamPosMode: LIN_HVACAct2Stat_ParamPosMode ;
  LIN_HVACAct2Stat_StatusEmRun: LIN_HVACAct2Stat_StatusEmRun ;
  LIN_HVACAct2Stat_StatusReset: LIN_HVACAct2Stat_StatusReset ;
  LIN_HVACAct2Stat_StatusStall: LIN_HVACAct2Stat_StatusStall ;
  LIN_HVACAct2Stat_StatusStallEn: LIN_HVACAct2Stat_StatusStallEn ;
  LIN_HVACAct3Stat_Conf2RunUpDir: LIN_HVACAct3Stat_Conf2RunUpDir ;
  LIN_HVACAct3Stat_Conf2SpecFnc: LIN_HVACAct3Stat_Conf2SpecFnc ;
  LIN_HVACAct3Stat_Conf2TorqueVar: LIN_HVACAct3Stat_Conf2TorqueVar ;
  LIN_HVACAct3Stat_ConfigDir: LIN_HVACAct3Stat_ConfigDir ;
  LIN_HVACAct3Stat_ConfigEmRun: LIN_HVACAct3Stat_ConfigEmRun ;
  LIN_HVACAct3Stat_ConfigEmRunDir: LIN_HVACAct3Stat_ConfigEmRunDir ;
  LIN_HVACAct3Stat_ConfigMode: LIN_HVACAct3Stat_ConfigMode ;
  LIN_HVACAct3Stat_ErrorElectr: LIN_HVACAct3Stat_ErrorElectr ;
  LIN_HVACAct3Stat_ErrorSupply: LIN_HVACAct3Stat_ErrorSupply ;
  LIN_HVACAct3Stat_ErrorTemp: LIN_HVACAct3Stat_ErrorTemp ;
  LIN_HVACAct3Stat_ParamCoils: LIN_HVACAct3Stat_ParamCoils ;
  LIN_HVACAct3Stat_ParamFreq: LIN_HVACAct3Stat_ParamFreq ;
  LIN_HVACAct3Stat_ParamPosMode: LIN_HVACAct3Stat_ParamPosMode ;
  LIN_HVACAct3Stat_StatusEmRun: LIN_HVACAct3Stat_StatusEmRun ;
  LIN_HVACAct3Stat_StatusReset: LIN_HVACAct3Stat_StatusReset ;
  LIN_HVACAct3Stat_StatusStall: LIN_HVACAct3Stat_StatusStall ;
  LIN_HVACAct3Stat_StatusStallEn: LIN_HVACAct3Stat_StatusStallEn ;
  LIN_HVACAct4Stat_Conf2RunUpDir: LIN_HVACAct4Stat_Conf2RunUpDir ;
  LIN_HVACAct4Stat_Conf2SpecFnc: LIN_HVACAct4Stat_Conf2SpecFnc ;
  LIN_HVACAct4Stat_Conf2TorqueVar: LIN_HVACAct4Stat_Conf2TorqueVar ;
  LIN_HVACAct4Stat_ConfigDir: LIN_HVACAct4Stat_ConfigDir ;
  LIN_HVACAct4Stat_ConfigEmRun: LIN_HVACAct4Stat_ConfigEmRun ;
  LIN_HVACAct4Stat_ConfigEmRunDir: LIN_HVACAct4Stat_ConfigEmRunDir ;
  LIN_HVACAct4Stat_ConfigMode: LIN_HVACAct4Stat_ConfigMode ;
  LIN_HVACAct4Stat_ErrorElectr: LIN_HVACAct4Stat_ErrorElectr ;
  LIN_HVACAct4Stat_ErrorSupply: LIN_HVACAct4Stat_ErrorSupply ;
  LIN_HVACAct4Stat_ErrorTemp: LIN_HVACAct4Stat_ErrorTemp ;
  LIN_HVACAct4Stat_ParamCoils: LIN_HVACAct4Stat_ParamCoils ;
  LIN_HVACAct4Stat_ParamFreq: LIN_HVACAct4Stat_ParamFreq ;
  LIN_HVACAct4Stat_ParamPosMode: LIN_HVACAct4Stat_ParamPosMode ;
  LIN_HVACAct4Stat_StatusEmRun: LIN_HVACAct4Stat_StatusEmRun ;
  LIN_HVACAct4Stat_StatusReset: LIN_HVACAct4Stat_StatusReset ;
  LIN_HVACAct4Stat_StatusStall: LIN_HVACAct4Stat_StatusStall ;
  LIN_HVACAct4Stat_StatusStallEn: LIN_HVACAct4Stat_StatusStallEn ;
  LIN_HVACAct5Stat_Conf2RunUpDir: LIN_HVACAct5Stat_Conf2RunUpDir ;
  LIN_HVACAct5Stat_Conf2SpecFnc: LIN_HVACAct5Stat_Conf2SpecFnc ;
  LIN_HVACAct5Stat_Conf2TorqueVar: LIN_HVACAct5Stat_Conf2TorqueVar ;
  LIN_HVACAct5Stat_ConfigDir: LIN_HVACAct5Stat_ConfigDir ;
  LIN_HVACAct5Stat_ConfigEmRun: LIN_HVACAct5Stat_ConfigEmRun ;
  LIN_HVACAct5Stat_ConfigEmRunDir: LIN_HVACAct5Stat_ConfigEmRunDir ;
  LIN_HVACAct5Stat_ConfigMode: LIN_HVACAct5Stat_ConfigMode ;
  LIN_HVACAct5Stat_ErrorElectr: LIN_HVACAct5Stat_ErrorElectr ;
  LIN_HVACAct5Stat_ErrorSupply: LIN_HVACAct5Stat_ErrorSupply ;
  LIN_HVACAct5Stat_ErrorTemp: LIN_HVACAct5Stat_ErrorTemp ;
  LIN_HVACAct5Stat_ParamCoils: LIN_HVACAct5Stat_ParamCoils ;
  LIN_HVACAct5Stat_ParamFreq: LIN_HVACAct5Stat_ParamFreq ;
  LIN_HVACAct5Stat_ParamPosMode: LIN_HVACAct5Stat_ParamPosMode ;
  LIN_HVACAct5Stat_StatusEmRun: LIN_HVACAct5Stat_StatusEmRun ;
  LIN_HVACAct5Stat_StatusReset: LIN_HVACAct5Stat_StatusReset ;
  LIN_HVACAct5Stat_StatusStall: LIN_HVACAct5Stat_StatusStall ;
  LIN_HVACAct5Stat_StatusStallEn: LIN_HVACAct5Stat_StatusStallEn ;
}
